VERSION ""

NS_ :

BS_:

BU_: XXX CAMERA FRONT_RADAR ADRV APRK

BO_ 53 ACCELERATOR: 32 XXX
 SG_ CHECKSUM : 0|16@1+ (1,0) [0|65535] "" XXX
 SG_ COUNTER : 16|8@1+ (1,0) [0|255] "" XXX
 SG_ ACCELERATOR_PEDAL : 40|8@1+ (1,0) [0|255] "" XXX
 SG_ GEAR : 192|3@1+ (1,0) [0|7] "" XXX

BO_ 64 GEAR_ALT: 32 XXX
 SG_ CHECKSUM : 0|16@1+ (1,0) [0|65535] "" XXX
 SG_ COUNTER : 16|8@1+ (1,0) [0|255] "" XXX
 SG_ GEAR : 32|3@1+ (1,0) [0|7] "" XXX

BO_ 69 GEAR: 24 XXX
 SG_ CHECKSUM : 0|16@1+ (1,0) [0|65535] "" XXX
 SG_ COUNTER : 16|8@1+ (1,0) [0|255] "" XXX
 SG_ GEAR : 44|3@1+ (1,0) [0|7] "" XXX

BO_ 96 ESP_STATUS: 32 XXX
 SG_ CHECKSUM : 0|16@1+ (1,0) [0|65535] "" XXX
 SG_ COUNTER : 16|8@1+ (1,0) [0|255] "" XXX
 SG_ TRACTION_AND_STABILITY_CONTROL : 42|3@1+ (1,0) [0|63] "" XXX
 SG_ BRAKE_PRESSURE : 128|10@1+ (1,0) [0|65535] "" XXX
 SG_ BRAKE_PRESSED : 148|1@1+ (1,0) [0|3] "" XXX

BO_ 101 BRAKE: 32 XXX
 SG_ CHECKSUM : 0|16@1+ (1,0) [0|65535] "" XXX
 SG_ COUNTER : 16|8@1+ (1,0) [0|255] "" XXX
 SG_ BRAKE_POSITION : 40|16@1- (1,0) [0|65535] "" XXX
 SG_ BRAKE_PRESSED : 57|1@1+ (1,0) [0|3] "" XXX

BO_ 160 WHEEL_SPEEDS: 24 XXX
 SG_ CHECKSUM : 0|16@1+ (1,0) [0|65535] "" XXX
 SG_ COUNTER : 16|8@1+ (1,0) [0|255] "" XXX
 SG_ MOVING_FORWARD : 56|1@0+ (1,0) [0|1] "" XXX
 SG_ MOVING_BACKWARD : 57|1@0+ (1,0) [0|1] "" XXX
 SG_ MOVING_FORWARD2 : 58|1@0+ (1,0) [0|1] "" XXX
 SG_ MOVING_BACKWARD2 : 59|1@0+ (1,0) [0|1] "" XXX
 SG_ WHL_SpdFLVal : 64|14@1+ (0.03125,0) [0|0] "km^h" XXX
 SG_ WHL_SpdFRVal : 80|14@1+ (0.03125,0) [0|0] "km^h" XXX
 SG_ WHL_SpdRLVal : 96|14@1+ (0.03125,0) [0|0] "km^h" XXX
 SG_ WHL_SpdRRVal : 112|14@1+ (0.03125,0) [0|0] "km^h" XXX

BO_ 256 ACCELERATOR_BRAKE_ALT: 32 XXX
 SG_ CHECKSUM : 0|16@1+ (1,0) [0|65535] "" XXX
 SG_ COUNTER : 16|8@1+ (1,0) [0|255] "" XXX
 SG_ BRAKE_PRESSED : 32|1@1+ (1,0) [0|1] "" XXX
 SG_ ACCELERATOR_PEDAL_PRESSED : 176|1@1+ (1,0) [0|1] "" XXX

BO_ 272 LKAS_ALT: 32 XXX
 SG_ CHECKSUM : 0|16@1+ (1,0) [0|65535] "" XXX
 SG_ COUNTER : 16|8@1+ (1,0) [0|255] "" XXX
 SG_ LKA_MODE : 24|3@1+ (1,0) [0|7] "" XXX
 SG_ LKA_AVAILABLE : 27|2@1+ (1,0) [0|255] "" XXX
 SG_ LKA_WARNING : 32|1@1+ (1,0) [0|1] "" XXX
 SG_ LKA_ICON : 38|2@1+ (1,0) [0|255] "" XXX
 SG_ FCA_SYSWARN : 40|1@0+ (1,0) [0|1] "" XXX
 SG_ TORQUE_REQUEST : 41|11@1+ (1,-1024) [0|4095] "" XXX
 SG_ STEER_REQ : 52|1@1+ (1,0) [0|1] "" XXX
 SG_ LFA_BUTTON : 56|1@1+ (1,0) [0|255] "" XXX
 SG_ LKA_ASSIST : 62|1@1+ (1,0) [0|1] "" XXX
 SG_ STEER_MODE : 65|3@1+ (1,0) [0|1] "" XXX
 SG_ NEW_SIGNAL_2 : 70|2@0+ (1,0) [0|3] "" XXX
 SG_ LKAS_ANGLE_ACTIVE : 77|2@0+ (1,0) [0|3] "" XXX
 SG_ HAS_LANE_SAFETY : 80|1@0+ (1,0) [0|1] "" XXX
 SG_ ADAS_StrAnglReqVal : 82|14@1- (0.1,0) [0|176.7] "Deg" GW_RGW,MDPS,SFA
 SG_ ADAS_ACIAnglTqRedcGainVal : 96|8@1+ (0.004,0) [0|1] "" GW_RGW,MDPS,SFA
 SG_ DAMP_FACTOR : 64|8@1+ (1,0) [0|255] "" XXX

BO_ 357 SPAS1: 24 APRK
 SG_ CHECKSUM : 0|16@1+ (1,0) [0|65535] "" XXX
 SG_ COUNTER : 16|8@1+ (1,0) [0|0] "" XXX
 SG_ NEW_SIGNAL_2 : 90|3@1+ (1,0) [0|0] "" XXX
 SG_ NEW_SIGNAL_1 : 96|16@1- (0.1,0) [0|0] "" XXX

BO_ 576 RADAR_0x240: 16 FRONT_RADAR
 SG_ CHECKSUM : 0|16@1+ (1,0) [0|65535] "" XXX
 SG_ COUNTER : 16|8@1+ (1,0) [0|255] "" XXX

BO_ 866 CAM_0x362: 32 CAMERA
 SG_ CHECKSUM : 0|16@1+ (1,0) [0|65535] "" XXX
 SG_ COUNTER : 16|8@1+ (1,0) [0|255] "" XXX
 SG_ BYTE3 : 24|8@1+ (1,0) [0|255] "" XXX
 SG_ BYTE4 : 32|8@1+ (1,0) [0|255] "" XXX
 SG_ BYTE5 : 40|8@1+ (1,0) [0|255] "" XXX
 SG_ BYTE6 : 48|8@1+ (1,0) [0|255] "" XXX
 SG_ LEFT_LANE_LINE : 56|2@1+ (1,0) [0|3] "" XXX
 SG_ SET_ME_0 : 58|2@1+ (1,0) [0|3] "" XXX
 SG_ RIGHT_LANE_LINE : 60|2@1+ (1,0) [0|3] "" XXX
 SG_ SET_ME_0_2 : 62|2@1+ (1,0) [0|3] "" XXX
 SG_ BYTE8 : 64|8@1+ (1,0) [0|255] "" XXX
 SG_ BYTE9 : 72|8@1+ (1,0) [0|255] "" XXX
 SG_ BYTE10 : 80|8@1+ (1,0) [0|255] "" XXX
 SG_ BYTE11 : 88|8@1+ (1,0) [0|255] "" XXX
 SG_ BYTE12 : 96|8@1+ (1,0) [0|255] "" XXX
 SG_ BYTE13 : 104|8@1+ (1,0) [0|255] "" XXX
 SG_ BYTE14 : 112|8@1+ (1,0) [0|255] "" XXX
 SG_ BYTE15 : 120|8@1+ (1,0) [0|255] "" XXX
 SG_ BYTE16 : 128|8@1+ (1,0) [0|255] "" XXX
 SG_ BYTE17 : 136|8@1+ (1,0) [0|255] "" XXX
 SG_ BYTE18 : 144|8@1+ (1,0) [0|255] "" XXX
 SG_ BYTE19 : 152|8@1+ (1,0) [0|255] "" XXX
 SG_ BYTE20 : 160|8@1+ (1,0) [0|255] "" XXX
 SG_ BYTE21 : 168|8@1+ (1,0) [0|255] "" XXX
 SG_ BYTE22 : 176|8@1+ (1,0) [0|255] "" XXX
 SG_ BYTE23 : 184|8@1+ (1,0) [0|255] "" XXX
 SG_ BYTE24 : 192|8@1+ (1,0) [0|255] "" XXX
 SG_ BYTE25 : 200|8@1+ (1,0) [0|255] "" XXX
 SG_ BYTE26 : 208|8@1+ (1,0) [0|255] "" XXX
 SG_ BYTE27 : 216|8@1+ (1,0) [0|255] "" XXX
 SG_ BYTE28 : 224|8@1+ (1,0) [0|255] "" XXX
 SG_ BYTE29 : 232|8@1+ (1,0) [0|255] "" XXX
 SG_ BYTE30 : 240|8@1+ (1,0) [0|255] "" XXX
 SG_ BYTE31 : 248|8@1+ (1,0) [0|255] "" XXX

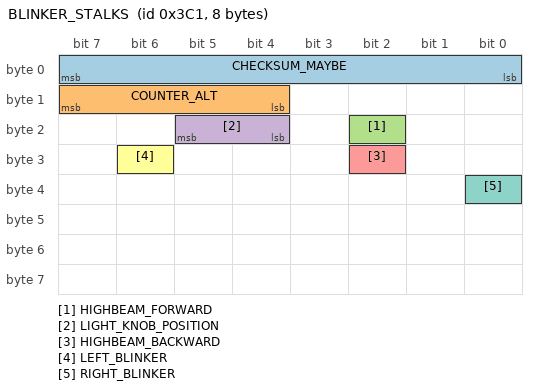
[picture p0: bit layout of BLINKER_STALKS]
BO_ 961 BLINKER_STALKS: 8 XXX
 SG_ CHECKSUM_MAYBE : 7|8@0+ (1,0) [0|255] "" XXX
 SG_ COUNTER_ALT : 15|4@0+ (1,0) [0|15] "" XXX
 SG_ HIGHBEAM_FORWARD : 18|1@0+ (1,0) [0|1] "" XXX
 SG_ LIGHT_KNOB_POSITION : 21|2@0+ (1,0) [0|3] "" XXX
 SG_ HIGHBEAM_BACKWARD : 26|1@0+ (1,0) [0|1] "" XXX
 SG_ LEFT_BLINKER : 30|1@0+ (1,0) [0|1] "" XXX
 SG_ RIGHT_BLINKER : 32|1@0+ (1,0) [0|1] "" XXX

BO_ 32 message_32: 8 Vector__XXX
 SG_ Signal_32 : 0|8@1+ (1,0) [0|0] "" Vector__XXX

BO_ 33 message_33: 8 Vector__XXX
 SG_ Signal_33 : 0|8@1+ (1,0) [0|0] "" Vector__XXX

BO_ 34 message_34: 8 Vector__XXX
 SG_ Signal_34 : 0|8@1+ (1,0) [0|0] "" Vector__XXX

BO_ 37 message_37: 8 Vector__XXX
 SG_ Signal_37 : 0|8@1+ (1,0) [0|0] "" Vector__XXX

BO_ 38 message_38: 8 Vector__XXX
 SG_ Signal_38 : 0|8@1+ (1,0) [0|0] "" Vector__XXX

BO_ 39 message_39: 8 Vector__XXX
 SG_ Signal_39 : 0|8@1+ (1,0) [0|0] "" Vector__XXX

BO_ 41 message_41: 8 Vector__XXX
 SG_ Signal_41 : 0|8@1+ (1,0) [0|0] "" Vector__XXX

BO_ 42 message_42: 8 Vector__XXX
 SG_ Signal_42 : 0|8@1+ (1,0) [0|0] "" Vector__XXX

BO_ 47 message_47: 8 Vector__XXX
 SG_ Signal_47 : 0|8@1+ (1,0) [0|0] "" Vector__XXX

BO_ 48 message_48: 8 Vector__XXX
 SG_ Signal_48 : 0|8@1+ (1,0) [0|0] "" Vector__XXX

BO_ 52 message_52: 8 Vector__XXX
 SG_ Signal_52 : 0|8@1+ (1,0) [0|0] "" Vector__XXX

BO_ 60 message_60: 8 Vector__XXX
 SG_ Signal_60 : 0|8@1+ (1,0) [0|0] "" Vector__XXX

BO_ 62 message_62: 8 Vector__XXX
 SG_ Signal_62 : 0|8@1+ (1,0) [0|0] "" Vector__XXX

BO_ 66 message_66: 8 Vector__XXX
 SG_ Signal_66 : 0|8@1+ (1,0) [0|0] "" Vector__XXX

BO_ 68 message_68: 8 Vector__XXX
 SG_ Signal_68 : 0|8@1+ (1,0) [0|0] "" Vector__XXX

BO_ 71 message_71: 8 Vector__XXX
 SG_ Signal_71 : 0|8@1+ (1,0) [0|0] "" Vector__XXX

BO_ 72 message_72: 8 Vector__XXX
 SG_ Signal_72 : 0|8@1+ (1,0) [0|0] "" Vector__XXX

BO_ 73 message_73: 8 Vector__XXX
 SG_ Signal_73 : 0|8@1+ (1,0) [0|0] "" Vector__XXX

BO_ 74 message_74: 8 Vector__XXX
 SG_ Signal_74 : 0|8@1+ (1,0) [0|0] "" Vector__XXX

BO_ 75 message_75: 8 Vector__XXX
 SG_ Signal_75 : 0|8@1+ (1,0) [0|0] "" Vector__XXX

BO_ 79 message_79: 8 Vector__XXX
 SG_ Signal_79 : 0|8@1+ (1,0) [0|0] "" Vector__XXX

BO_ 82 message_82: 8 Vector__XXX
 SG_ Signal_82 : 0|8@1+ (1,0) [0|0] "" Vector__XXX

BO_ 88 message_88: 8 Vector__XXX
 SG_ Signal_88 : 0|8@1+ (1,0) [0|0] "" Vector__XXX

BO_ 90 message_90: 8 Vector__XXX
 SG_ Signal_90 : 0|8@1+ (1,0) [0|0] "" Vector__XXX

BO_ 97 message_97: 8 Vector__XXX
 SG_ Signal_97 : 0|8@1+ (1,0) [0|0] "" Vector__XXX

BO_ 100 message_100: 8 Vector__XXX
 SG_ Signal_100 : 0|8@1+ (1,0) [0|0] "" Vector__XXX

BO_ 116 message_116: 8 Vector__XXX
 SG_ Signal_116 : 0|8@1+ (1,0) [0|0] "" Vector__XXX

BO_ 117 message_117: 8 Vector__XXX
 SG_ Signal_117 : 0|8@1+ (1,0) [0|0] "" Vector__XXX

BO_ 118 message_118: 8 Vector__XXX
 SG_ Signal_118 : 0|8@1+ (1,0) [0|0] "" Vector__XXX

BO_ 119 message_119: 8 Vector__XXX
 SG_ Signal_119 : 0|8@1+ (1,0) [0|0] "" Vector__XXX

BO_ 125 message_125: 8 Vector__XXX
 SG_ Signal_125 : 0|8@1+ (1,0) [0|0] "" Vector__XXX

BO_ 126 message_126: 8 Vector__XXX
 SG_ Signal_126 : 0|8@1+ (1,0) [0|0] "" Vector__XXX

BO_ 127 message_127: 8 Vector__XXX
 SG_ Signal_127 : 0|8@1+ (1,0) [0|0] "" Vector__XXX

BO_ 128 message_128: 8 Vector__XXX
 SG_ Signal_128 : 0|8@1+ (1,0) [0|0] "" Vector__XXX

BO_ 129 message_129: 8 Vector__XXX
 SG_ Signal_129 : 0|8@1+ (1,0) [0|0] "" Vector__XXX

BO_ 130 message_130: 8 Vector__XXX
 SG_ Signal_130 : 0|8@1+ (1,0) [0|0] "" Vector__XXX

BO_ 140 message_140: 8 Vector__XXX
 SG_ Signal_140 : 0|8@1+ (1,0) [0|0] "" Vector__XXX

BO_ 145 message_145: 8 Vector__XXX
 SG_ Signal_145 : 0|8@1+ (1,0) [0|0] "" Vector__XXX

BO_ 148 message_148: 8 Vector__XXX
 SG_ Signal_148 : 0|8@1+ (1,0) [0|0] "" Vector__XXX

BO_ 171 message_171: 8 Vector__XXX
 SG_ Signal_171 : 0|8@1+ (1,0) [0|0] "" Vector__XXX

BO_ 172 message_172: 8 Vector__XXX
 SG_ Signal_172 : 0|8@1+ (1,0) [0|0] "" Vector__XXX

BO_ 173 message_173: 8 Vector__XXX
 SG_ Signal_173 : 0|8@1+ (1,0) [0|0] "" Vector__XXX

BO_ 175 message_175: 8 Vector__XXX
 SG_ Signal_175 : 0|8@1+ (1,0) [0|0] "" Vector__XXX

BO_ 177 message_177: 8 Vector__XXX
 SG_ Signal_177 : 0|8@1+ (1,0) [0|0] "" Vector__XXX

BO_ 178 message_178: 8 Vector__XXX
 SG_ Signal_178 : 0|8@1+ (1,0) [0|0] "" Vector__XXX

BO_ 182 message_182: 8 Vector__XXX
 SG_ Signal_182 : 0|8@1+ (1,0) [0|0] "" Vector__XXX

BO_ 184 message_184: 8 Vector__XXX
 SG_ Signal_184 : 0|8@1+ (1,0) [0|0] "" Vector__XXX

BO_ 185 message_185: 8 Vector__XXX
 SG_ Signal_185 : 0|8@1+ (1,0) [0|0] "" Vector__XXX

BO_ 186 message_186: 8 Vector__XXX
 SG_ Signal_186 : 0|8@1+ (1,0) [0|0] "" Vector__XXX

BO_ 194 message_194: 8 Vector__XXX
 SG_ Signal_194 : 0|8@1+ (1,0) [0|0] "" Vector__XXX

BO_ 204 message_204: 8 Vector__XXX
 SG_ Signal_204 : 0|8@1+ (1,0) [0|0] "" Vector__XXX

BO_ 209 message_209: 8 Vector__XXX
 SG_ Signal_209 : 0|8@1+ (1,0) [0|0] "" Vector__XXX

BO_ 221 message_221: 8 Vector__XXX
 SG_ Signal_221 : 0|8@1+ (1,0) [0|0] "" Vector__XXX

BO_ 240 message_240: 8 Vector__XXX
 SG_ Signal_240 : 0|8@1+ (1,0) [0|0] "" Vector__XXX

BO_ 247 message_247: 8 Vector__XXX
 SG_ Signal_247 : 0|8@1+ (1,0) [0|0] "" Vector__XXX

BO_ 258 message_258: 8 Vector__XXX
 SG_ Signal_258 : 0|8@1+ (1,0) [0|0] "" Vector__XXX

BO_ 268 message_268: 8 Vector__XXX
 SG_ Signal_268 : 0|8@1+ (1,0) [0|0] "" Vector__XXX

BO_ 285 message_285: 8 Vector__XXX
 SG_ Signal_285 : 0|8@1+ (1,0) [0|0] "" Vector__XXX

BO_ 303 message_303: 8 Vector__XXX
 SG_ Signal_303 : 0|8@1+ (1,0) [0|0] "" Vector__XXX

BO_ 321 message_321: 8 Vector__XXX
 SG_ Signal_321 : 0|8@1+ (1,0) [0|0] "" Vector__XXX

BO_ 327 message_327: 8 Vector__XXX
 SG_ Signal_327 : 0|8@1+ (1,0) [0|0] "" Vector__XXX

BO_ 328 message_328: 8 Vector__XXX
 SG_ Signal_328 : 0|8@1+ (1,0) [0|0] "" Vector__XXX

BO_ 560 message_560: 8 Vector__XXX
 SG_ Signal_560 : 0|8@1+ (1,0) [0|0] "" Vector__XXX

BO_ 565 message_565: 8 Vector__XXX
 SG_ Signal_565 : 0|8@1+ (1,0) [0|0] "" Vector__XXX

BO_ 566 message_566: 8 Vector__XXX
 SG_ Signal_566 : 0|8@1+ (1,0) [0|0] "" Vector__XXX

BO_ 567 message_567: 8 Vector__XXX
 SG_ Signal_567 : 0|8@1+ (1,0) [0|0] "" Vector__XXX

BO_ 568 message_568: 8 Vector__XXX
 SG_ Signal_568 : 0|8@1+ (1,0) [0|0] "" Vector__XXX

BO_ 569 message_569: 8 Vector__XXX
 SG_ Signal_569 : 0|8@1+ (1,0) [0|0] "" Vector__XXX

BO_ 570 message_570: 8 Vector__XXX
 SG_ Signal_570 : 0|8@1+ (1,0) [0|0] "" Vector__XXX

BO_ 571 message_571: 8 Vector__XXX
 SG_ Signal_571 : 0|8@1+ (1,0) [0|0] "" Vector__XXX

BO_ 572 message_572: 8 Vector__XXX
 SG_ Signal_572 : 0|8@1+ (1,0) [0|0] "" Vector__XXX

BO_ 573 message_573: 8 Vector__XXX
 SG_ Signal_573 : 0|8@1+ (1,0) [0|0] "" Vector__XXX

BO_ 574 message_574: 8 Vector__XXX
 SG_ Signal_574 : 0|8@1+ (1,0) [0|0] "" Vector__XXX

BO_ 575 message_575: 8 Vector__XXX
 SG_ Signal_575 : 0|8@1+ (1,0) [0|0] "" Vector__XXX

BO_ 577 message_577: 8 Vector__XXX
 SG_ Signal_577 : 0|8@1+ (1,0) [0|0] "" Vector__XXX

BO_ 578 message_578: 8 Vector__XXX
 SG_ Signal_578 : 0|8@1+ (1,0) [0|0] "" Vector__XXX

BO_ 579 message_579: 8 Vector__XXX
 SG_ Signal_579 : 0|8@1+ (1,0) [0|0] "" Vector__XXX

BO_ 580 message_580: 8 Vector__XXX
 SG_ Signal_580 : 0|8@1+ (1,0) [0|0] "" Vector__XXX

BO_ 581 message_581: 8 Vector__XXX
 SG_ Signal_581 : 0|8@1+ (1,0) [0|0] "" Vector__XXX

BO_ 582 message_582: 8 Vector__XXX
 SG_ Signal_582 : 0|8@1+ (1,0) [0|0] "" Vector__XXX

BO_ 583 message_583: 8 Vector__XXX
 SG_ Signal_583 : 0|8@1+ (1,0) [0|0] "" Vector__XXX

BO_ 584 message_584: 8 Vector__XXX
 SG_ Signal_584 : 0|8@1+ (1,0) [0|0] "" Vector__XXX

BO_ 752 message_752: 8 Vector__XXX
 SG_ Signal_752 : 0|8@1+ (1,0) [0|0] "" Vector__XXX

BO_ 768 message_768: 8 Vector__XXX
 SG_ Signal_768 : 0|8@1+ (1,0) [0|0] "" Vector__XXX

BO_ 771 message_771: 8 Vector__XXX
 SG_ Signal_771 : 0|8@1+ (1,0) [0|0] "" Vector__XXX

BO_ 864 message_864: 8 Vector__XXX
 SG_ Signal_864 : 0|8@1+ (1,0) [0|0] "" Vector__XXX

BO_ 865 message_865: 8 Vector__XXX
 SG_ Signal_865 : 0|8@1+ (1,0) [0|0] "" Vector__XXX

BO_ 867 message_867: 8 Vector__XXX
 SG_ Signal_867 : 0|8@1+ (1,0) [0|0] "" Vector__XXX

BO_ 868 message_868: 8 Vector__XXX
 SG_ Signal_868 : 0|8@1+ (1,0) [0|0] "" Vector__XXX

BO_ 896 message_896: 8 Vector__XXX
 SG_ Signal_896 : 0|8@1+ (1,0) [0|0] "" Vector__XXX

BO_ 917 message_917: 8 Vector__XXX
 SG_ Signal_917 : 0|8@1+ (1,0) [0|0] "" Vector__XXX

BO_ 928 message_928: 8 Vector__XXX
 SG_ Signal_928 : 0|8@1+ (1,0) [0|0] "" Vector__XXX

BO_ 933 message_933: 8 Vector__XXX
 SG_ Signal_933 : 0|8@1+ (1,0) [0|0] "" Vector__XXX

BO_ 934 message_934: 8 Vector__XXX
 SG_ Signal_934 : 0|8@1+ (1,0) [0|0] "" Vector__XXX

BO_ 935 message_935: 8 Vector__XXX
 SG_ Signal_935 : 0|8@1+ (1,0) [0|0] "" Vector__XXX

BO_ 936 message_936: 8 Vector__XXX
 SG_ Signal_936 : 0|8@1+ (1,0) [0|0] "" Vector__XXX

BO_ 937 message_937: 8 Vector__XXX
 SG_ Signal_937 : 0|8@1+ (1,0) [0|0] "" Vector__XXX

BO_ 938 message_938: 8 Vector__XXX
 SG_ Signal_938 : 0|8@1+ (1,0) [0|0] "" Vector__XXX

BO_ 939 message_939: 8 Vector__XXX
 SG_ Signal_939 : 0|8@1+ (1,0) [0|0] "" Vector__XXX

BO_ 940 message_940: 8 Vector__XXX
 SG_ Signal_940 : 0|8@1+ (1,0) [0|0] "" Vector__XXX

BO_ 941 message_941: 8 Vector__XXX
 SG_ Signal_941 : 0|8@1+ (1,0) [0|0] "" Vector__XXX

BO_ 942 message_942: 8 Vector__XXX
 SG_ Signal_942 : 0|8@1+ (1,0) [0|0] "" Vector__XXX

BO_ 943 message_943: 8 Vector__XXX
 SG_ Signal_943 : 0|8@1+ (1,0) [0|0] "" Vector__XXX

BO_ 944 message_944: 8 Vector__XXX
 SG_ Signal_944 : 0|8@1+ (1,0) [0|0] "" Vector__XXX

BO_ 945 message_945: 8 Vector__XXX
 SG_ Signal_945 : 0|8@1+ (1,0) [0|0] "" Vector__XXX

BO_ 946 message_946: 8 Vector__XXX
 SG_ Signal_946 : 0|8@1+ (1,0) [0|0] "" Vector__XXX

BO_ 947 message_947: 8 Vector__XXX
 SG_ Signal_947 : 0|8@1+ (1,0) [0|0] "" Vector__XXX

BO_ 948 message_948: 8 Vector__XXX
 SG_ Signal_948 : 0|8@1+ (1,0) [0|0] "" Vector__XXX

BO_ 949 message_949: 8 Vector__XXX
 SG_ Signal_949 : 0|8@1+ (1,0) [0|0] "" Vector__XXX

BO_ 950 message_950: 8 Vector__XXX
 SG_ Signal_950 : 0|8@1+ (1,0) [0|0] "" Vector__XXX

BO_ 951 message_951: 8 Vector__XXX
 SG_ Signal_951 : 0|8@1+ (1,0) [0|0] "" Vector__XXX

BO_ 952 message_952: 8 Vector__XXX
 SG_ Signal_952 : 0|8@1+ (1,0) [0|0] "" Vector__XXX

BO_ 953 message_953: 8 Vector__XXX
 SG_ Signal_953 : 0|8@1+ (1,0) [0|0] "" Vector__XXX

BO_ 954 message_954: 8 Vector__XXX
 SG_ Signal_954 : 0|8@1+ (1,0) [0|0] "" Vector__XXX

BO_ 955 message_955: 8 Vector__XXX
 SG_ Signal_955 : 0|8@1+ (1,0) [0|0] "" Vector__XXX

BO_ 956 message_956: 8 Vector__XXX
 SG_ Signal_956 : 0|8@1+ (1,0) [0|0] "" Vector__XXX

BO_ 957 message_957: 8 Vector__XXX
 SG_ Signal_957 : 0|8@1+ (1,0) [0|0] "" Vector__XXX

BO_ 958 message_958: 8 Vector__XXX
 SG_ Signal_958 : 0|8@1+ (1,0) [0|0] "" Vector__XXX

BO_ 959 message_959: 8 Vector__XXX
 SG_ Signal_959 : 0|8@1+ (1,0) [0|0] "" Vector__XXX

BO_ 960 message_960: 8 Vector__XXX
 SG_ Signal_960 : 0|8@1+ (1,0) [0|0] "" Vector__XXX

BO_ 962 message_962: 8 Vector__XXX
 SG_ Signal_962 : 0|8@1+ (1,0) [0|0] "" Vector__XXX

BO_ 963 message_963: 8 Vector__XXX
 SG_ Signal_963 : 0|8@1+ (1,0) [0|0] "" Vector__XXX

BO_ 964 message_964: 8 Vector__XXX
 SG_ Signal_964 : 0|8@1+ (1,0) [0|0] "" Vector__XXX

BO_ 975 message_975: 8 Vector__XXX
 SG_ Signal_975 : 0|8@1+ (1,0) [0|0] "" Vector__XXX

BO_ 976 message_976: 8 Vector__XXX
 SG_ Signal_976 : 0|8@1+ (1,0) [0|0] "" Vector__XXX

BO_ 977 message_977: 8 Vector__XXX
 SG_ Signal_977 : 0|8@1+ (1,0) [0|0] "" Vector__XXX

BO_ 978 message_978: 8 Vector__XXX
 SG_ Signal_978 : 0|8@1+ (1,0) [0|0] "" Vector__XXX

BO_ 979 message_979: 8 Vector__XXX
 SG_ Signal_979 : 0|8@1+ (1,0) [0|0] "" Vector__XXX

BO_ 980 message_980: 8 Vector__XXX
 SG_ Signal_980 : 0|8@1+ (1,0) [0|0] "" Vector__XXX

BO_ 984 message_984: 8 Vector__XXX
 SG_ Signal_984 : 0|8@1+ (1,0) [0|0] "" Vector__XXX

BO_ 1024 message_1024: 8 Vector__XXX
 SG_ Signal_1024 : 0|8@1+ (1,0) [0|0] "" Vector__XXX

BO_ 1200 message_1200: 8 Vector__XXX
 SG_ Signal_1200 : 0|8@1+ (1,0) [0|0] "" Vector__XXX

BO_ 1280 message_1280: 8 Vector__XXX
 SG_ Signal_1280 : 0|8@1+ (1,0) [0|0] "" Vector__XXX

CM_ "AUTOGENERATED FILE, DO NOT EDIT";
CM_ "Imported file _hyundai_canfd_common.dbc starts here";
CM_ BO_ 676 "Contains signals with detailed lane line information. Used by ADAS ECU on HDA 2 vehicles to operate LFA.";

CM_ SG_ 80 HAS_LANE_SAFETY "If 0, hides LKAS 'Lane Safety' menu from vehicle settings";
CM_ SG_ 676 LEFT_LANE_LINE "Left lane line confidence";
CM_ SG_ 676 RIGHT_LANE_LINE "Right lane line confidence";
VAL_ 80 LKA_ICON 0 "hidden" 1 "grey" 2 "green" 3 "flashing green" ;
VAL_ 80 LKA_MODE 1 "warning only" 2 "assist" 6 "off" ;
VAL_ 676 LEFT_LANE_LINE 0 "Not Detected" 1 "Low Confidence" 2 "Medium Confidence" 3 "High Confidence";
VAL_ 676 RIGHT_LANE_LINE 0 "Not Detected" 1 "Low Confidence" 2 "Medium Confidence" 3 "High Confidence";

CM_ "hyundai_canfd.dbc starts here";

CM_ SG_ 96 BRAKE_PRESSURE "User applied brake pedal pressure. Ramps from computer applied pressure on falling edge of cruise. Cruise cancels if !=0";
CM_ SG_ 101 BRAKE_POSITION "User applied brake pedal position, max is ~700. Signed on some vehicles";
CM_ SG_ 203 ADAS_ActvACISta "ADAS Active AngleControlInterface State";
CM_ SG_ 203 ADAS_ActvACILvl2Sta "ADAS Active AngleControlInterface Level 2 State";
CM_ SG_ 203 ADAS_StrAnglReqVal "(LFA) ADAS Steering Angle Request Value; Capped at 119.9;";
CM_ SG_ 203 ADAS_ACIAnglTqRedcGainVal "(LFA) ADAS AngleControlInterface Angle Torque Reduction Gain Value";
CM_ SG_ 203 FCA_ESA_ActvSta "FCA_ESA Active State";
CM_ SG_ 203 FCA_ESA_TqBstGainVal "FCA_ESA Torque Boost Gain Value";
CM_ BO_ 272 "Alternative LKAS message, used on cars such as 2023 Ioniq 6, 2nd gen Kona. Matches LKAS except size is 32 bytes";
CM_ SG_ 272 LKA_AVAILABLE "Angle control cars: 3 when LKA is generally available, goes to 0 during changes with LFA";
CM_ SG_ 272 ADAS_StrAnglReqVal "(LKAS) ADAS Steering Angle Request Value; Capped at 176.7; tracks MDPS->STEERING_ANGLE when not engaged, not STEERING_SENSORS->STEERING_ANGLE";
CM_ SG_ 272 ADAS_ACIAnglTqRedcGainVal "(LKAS) ADAS AngleControlInterface Angle Torque Reduction Gain Value";
CM_ BO_ 282 "Sent by the camera containing DAW (Driver Attention Warning) information and information about HBA (High Beam Assist).";
CM_ SG_ 282 FR_CMR_Crc1Val "The data area for CRC calculation is based on the data length (DLC) of the message DB. The CRC shall be calculated over the entire data block (excluding the CRC bytes) including the user data, alive counter and Data ID - CRC Polynomial (0x1021) , In";
CM_ SG_ 282 FR_CMR_AlvCnt1Val "For the first transmission request for a data element the counter shall be initialized with 0 and shall be incremented by 1 for every subsequent send request. When the counter reaches the maximum value(0xFF), then it shall restart with 0 for the next s";
CM_ SG_ 282 HBA_SysOptSta "HBA System Option Information to Lamp Controller";
CM_ SG_ 282 HBA_SysSta "This signal indicates the status of High Beam Assist system.";
CM_ SG_ 282 HBA_IndLmpReq "HBA System Indicator Lamp Status";
CM_ SG_ 282 FCA_Equip_MFC "FCA Sensor Type";
CM_ SG_ 282 HBA_OptUsmSta "HBA Option USM Status";
CM_ SG_ 282 DAW_LVDA_PUDis "Message for displaying LVDA(Leading Vehicle Departure Alert) Warning";
CM_ SG_ 282 DAW_LVDA_OptUsmSta "LVDA USM state";
CM_ SG_ 282 DAW_OptUsmSta "This signal represents the lastest DAW ON/OFF value of USM.";
CM_ SG_ 282 DAW_SysSta "This signal represents Attention Assist System Status or Attention Level.";
CM_ SG_ 282 DAW_WrnMsgSta "0x1 value requests DAW Rest recommend warning message popup at CLU. 0x2 value requests HDA/LFA Hands-Off call at TMS.";
CM_ SG_ 282 DAW_TimeRstReq "This signal requests CLU 'Last Break Time' Reset. DAW send '0x1' when detecting driver's rest.";
CM_ SG_ 282 DAW_SnstvtyModRetVal "This signal represents the feedback value of the current ADAS warning timing.";
CM_ SG_ 282 FR_CMR_SCCEquipSta "This signal indicates equipment for SCC";
CM_ SG_ 282 FR_CMR_ReqADASMapMsgVal "This signal indicates an ADAS map message request from FR_CMR to H_U. Each bit indicates the request messages as follows. - Bit 0 : H_U_NAVI_V2_STUB_E - Bit 1 : HU_NAVI_V2_PROSHORT_E_00 (곡률) - Bit 2 : HU_NAVI_V2_PROSHORT_E_00 (곡률 외 정보)";
CM_ SG_ 282 FR_CMR_SwVer1Val "This signal indicates a major version of FR_CMR software. If FR_CMR software version is A.00, 'A' and '00' mean major and minor version respectively.";
CM_ SG_ 282 FR_CMR_SwVer2Val "This signal indicates a minor version of FR_CMR software. If FR_CMR software version is A.00, 'A' and '00' mean major and minor version respectively.";
CM_ SG_ 298 NEW_SIGNAL_4 "todo: figure out why always set to 9";
CM_ SG_ 352 SET_ME_9 "has something to do with AEB settings";
CM_ SG_ 373 ACCEnable "Likely a copy of CAN's TCS13->ACCEnable";
CM_ SG_ 373 DriverBraking "Likely derived from BRAKE->BRAKE_POSITION";
CM_ SG_ 373 DriverBrakingLowSens "Higher threshold version of DriverBraking";
CM_ SG_ 373 PROBABLY_EQUIP "aeb equip?";
CM_ SG_ 416 VSetDis "set speed in display units";
CM_ BO_ 437 "Sent by the camera containing lane and lead information.";
CM_ SG_ 437 FR_CMR_Crc3Val "The data area for CRC calculation is based on the data length (DLC) of the message DB. The CRC shall be calculated over the entire data block (excluding the CRC bytes) including the user data, alive counter and Data ID - CRC Polynomial (0x1021) , In";
CM_ SG_ 437 FR_CMR_AlvCnt3Val "For the first transmission request for a data element the counter shall be initialized with 0 and shall be incremented by 1 for every subsequent send request. When the counter reaches the maximum value(0xFF), then it shall restart with 0 for the next s";
CM_ SG_ 437 Info_LftLnQualSta "This signal indicates the quality of left line.";
CM_ SG_ 437 Info_LftLnDptSta "This signal indicates the lane departure status of left line.";
CM_ SG_ 437 Info_LftLnPosVal "This signal outputs the position of left line from camera center.";
CM_ SG_ 437 Info_LftLnHdingAnglVal "This signal outputs the heading angle of left line.";
CM_ SG_ 437 Info_LftLnCvtrVal "This signal outputs the curvature of left line.";
CM_ SG_ 437 Info_RtLnQualSta "This signal indicates the quality of right line.";
CM_ SG_ 437 Info_RtLnDptSta "This signal indicates the lane departure status of right line.";
CM_ SG_ 437 Info_RtLnPosVal "This signal outputs the position of right line from camera center.";
CM_ SG_ 437 Info_RtLnHdingAnglVal "This signal outputs the heading angle of right line.";
CM_ SG_ 437 Info_RtLnCvtrVal "This signal outputs the curvature of right line.";
CM_ SG_ 437 ID_CIPV "Valid Object = 1 to 255 - ID detected by front camera can vary depending on vehicle environment. - Additional logic would be required to apply this signal for ISG.";
CM_ SG_ 437 Relative_Velocity "+ : Preceding, - : Oncoming - Velocity detected by front camera can vary depending on vehicle environment. - Additional logic would be required to apply this signal for ISG. - Confirmaiton by Autonomous Driving Engineering Team is required to use ID_C";
CM_ SG_ 480 NEW_SIGNAL_5 "todo: figure out why always set to 1";
CM_ BO_ 506 "Sent by the camera containing speed limit information. ISLW stands for Intelligent Speed Limit Warning, and ISLA is Intelligent Speed Limit Assist. it also contains road sign information.";
CM_ SG_ 506 FR_CMR_Crc2Val "The data area for CRC calculation is based on the data length (DLC) of the message DB.The CRC shall be calculated over the entire data block (excluding the CRC bytes) including the user data, alive counter and Data ID - CRC Polynomial (0x1021) , In";
CM_ SG_ 506 FR_CMR_AlvCnt2Val "For the first transmission request for a data element the counter shall be initialized with 0 and shall be incremented by 1 for every subsequent send request. When the counter reaches the maximum value(0xFF), then it shall restart with 0 for the next s";
CM_ SG_ 506 ISLW_OptUsmSta "ISLW option information";
CM_ SG_ 506 ISLW_SysSta "Validity of ISLW information";
CM_ SG_ 506 ISLW_NoPassingInfoDis "This signal indicates additional information of ISLW. For example no passing.";
CM_ SG_ 506 ISLW_OvrlpSignDis "indicates presence of Overlap sign";
CM_ SG_ 506 ISLW_SpdCluMainDis "Main Speed Information for cluster display in main page(0x1~0xFCH: 1*(HEX VALUE) [KPH or MPH :Reference signal is  CF_Clu_SPEED_UNIT of CLU])";
CM_ SG_ 506 ISLW_SpdNaviMainDis "Main Speed information for navigation display in main page(0x1~0xFCH: 1*(HEX VALUE) [KPH or MPH :Reference signal is  Navi_ISLW_SpdUnit of Navigation)";
CM_ SG_ 506 ISLW_SubCondinfoSta1 "Indicates 1st conditional traffic sign status";
CM_ SG_ 506 ISLW_SubCondinfoSta2 "Indicates 2nd conditional traffic sign status";
CM_ SG_ 506 ISLW_SpdCluSubMainDis "Main Speed Information for cluster display in ISLW detail page";
CM_ SG_ 506 ISLW_SpdCluDisSubCond1 "Indicates conditional speed limit/no passing of 1st conditional traffic sign for Cluster in ISLW Detail page";
CM_ SG_ 506 ISLW_SpdCluDisSubCond2 "Indicates conditional speed limit/no passing of 2nd conditional traffic sign for Cluster in ISLW Detail page";
CM_ SG_ 506 ISLW_SpdNaviSubMainDis "Main Speed Information for NAVI display in ISLW detail page";
CM_ SG_ 506 ISLW_SpdNaviDisSubCond1 "Indicates conditional speed limit/no passing of 1st conditional traffic sign for NAVI in ISLW Detail page";
CM_ SG_ 506 ISLW_SpdNaviDisSubCond2 "Indicates conditional speed limit/no passing of 2nd conditional traffic sign for NAVI in ISLW Detail page";
CM_ SG_ 506 ISLA_SpdwOffst "This is a ISLA speed with offset to change the set speed of MSLA/CC/SCC.Unit (kph or mph) refers to cluster signal: CLU_SpdUnitTyp@CLU_01_20ms";
CM_ SG_ 506 ISLA_SwIgnoreReq "This is a signal requesting to ignore the -(SET) or +(SET) switch input of the driver.";
CM_ SG_ 506 ISLA_SpdChgReq "This is a signal requesting to change the set speed of MSLA/CC/SCC to the ISLA speed.";
CM_ SG_ 506 ISLA_SpdWrn "This is a warning signal when VANZ exceeds the speed limit.";
CM_ SG_ 506 ISLA_IcyWrn "This is a warning signal when the snow or ice sign is recognized when it is less than 4 'C.";
CM_ SG_ 506 ISLA_SymFlashMod "This is a signal for the flashing mode of the symbol.";
CM_ SG_ 506 ISLA_Popup "This is a signal for ISLA pop-up.";
CM_ SG_ 506 ISLA_OptUsmSta "This is a ISLA option USM signal set by the driver.";
CM_ SG_ 506 ISLA_OffstUsmSta "This is a signal for offset speed set by the driver. Unit (kph or mph) refers to cluster signal: CLU_SpdUnitTyp@CLU_01_20ms";
CM_ SG_ 506 ISLA_AutoUsmSta "This is a signal for ISLA AUTO USM set by the driver.";
CM_ SG_ 506 ISLA_Cntry "This is a signal for categorizing countries";
CM_ SG_ 506 ISLA_AddtnlSign "This is a signal for additional sign";
CM_ SG_ 506 ISLA_SchoolZone "This is a signal for School Zone";
CM_ SG_ 687 HOD_Dir_Status "This signal indicates the status of hands on/off";
CM_ BO_ 698 "Sent by the camera containing information about vehicles in front of us. IFS stands for Intelligent Front-lighting System, and this signal provides the information necessary for it to operate.";
CM_ SG_ 698 FR_CMR_Crc4Val "The data area for CRC calculation is based on the data length (DLC) of the message DB. The CRC shall be calculated over the entire data block (excluding the CRC bytes) including the user data, alive counter and Data ID - CRC Polynomial (0x1021) , In";
CM_ SG_ 698 FR_CMR_AlvCnt4Val "For the first transmission request for a data element the counter shall be initialized with 0 and shall be incremented by 1 for every subsequent send request. When the counter reaches the maximum value(0xFF), then it shall restart with 0 for the next s";
CM_ SG_ 698 IFSref_FR_CMR_Sta "This is IFS system status needed for operate the IFS function of headlamp highbeam";
CM_ SG_ 698 IFSref_VehNumVal "This is number of vehicles detected from camera";
CM_ SG_ 698 IFSref_ILLAmbtSta "This signal is status of the ambient brightness 0x0 is bright condition (HighBeam off), 0x1 is dark condition (None)";
CM_ SG_ 698 IFSref_VehLftAngl1Val "This is left angle of vehicle 1 Deg = (HEX)*0.1-25";
CM_ SG_ 698 IFSref_VehRtAngl1Val "This is right angle of vehicle 1 Deg = (HEX)*0.1-25";
CM_ SG_ 698 IFSref_VehLftAngl2Val "This is left angle of vehicle 2 Deg = (HEX)*0.1-25";
CM_ SG_ 698 IFSref_VehDst1Val "IFSref_VehicleDistance1Value";
CM_ SG_ 698 IFSref_VehRtAngl2Val "This is right angle of vehicle 2 Deg = (HEX)*0.1-25";
CM_ SG_ 698 IFSref_VehLftAngl3Val "This is left angle of vehicle 3 Deg = (HEX)*0.1-25";
CM_ SG_ 698 IFSref_VehRtAngl3Val "This is right angle of vehicle 3 Deg = (HEX)*0.1-25";
CM_ SG_ 698 IFSref_VehLftAngl4Val "This is left angle of vehicle 4 Deg = (HEX)*0.1-25";
CM_ SG_ 698 IFSref_VehRtAngl4Val "This is right angle of vehicle 4 Deg = (HEX)*0.1-25";
CM_ SG_ 698 IFSref_VehLftAngl5Val "This is left angle of vehicle 5 Deg = (HEX)*0.1-25";
CM_ SG_ 698 IFSref_VehRtAngl5Val "This is right angle of vehicle 5 Deg = (HEX)*0.1-25";
CM_ SG_ 698 IFSref_VehLftAngl6Val "This is left angle of vehicle 6 Deg = (HEX)*0.1-25";
CM_ SG_ 698 IFSref_VehRtAngl6Val "This is right angle of vehicle 6 Deg = (HEX)*0.1-25";
CM_ SG_ 698 IFSref_VehLftAngl7Val "This is left angle of vehicle 7 Deg = (HEX)*0.1-25";
CM_ SG_ 698 IFSref_VehRtAngl7Val "This is right angle of vehicle 7 Deg = (HEX)*0.1-25";
CM_ SG_ 698 IFSref_VehLftAngl8Val "This is left angle of vehicle 8 Deg = (HEX)*0.1-25";
CM_ SG_ 698 IFSref_VehRtAngl8Val "This is right angle of vehicle 8 Deg = (HEX)*0.1-25";
CM_ SG_ 698 IFSref_VehLftAngl9Val "This is left angle of vehicle 9 Deg = (HEX)*0.1-25";
CM_ SG_ 698 IFSref_VehRtAngl9Val "This is right angle of vehicle 9 Deg = (HEX)*0.1-25";
CM_ SG_ 698 IFSref_VehLftAngl10Val "This is left angle of vehicle 10 Deg = (HEX)*0.1-25";
CM_ SG_ 698 IFSref_VehRtAngl10Val "This is right angle of vehicle 10 Deg = (HEX)*0.1-25";
CM_ SG_ 698 IFSref_VehDst2Val "IFSref_VehicleDistance2Value";
CM_ SG_ 698 IFSref_VehDst3Val "IFSref_VehicleDistance3Value";
CM_ SG_ 698 IFSref_VehDst4Val "IFSref_VehicleDistance4Value";
CM_ SG_ 698 IFSref_VehDst5Val "IFSref_VehicleDistance5Value";
CM_ SG_ 698 IFSref_VehDst6Val "IFSref_VehicleDistance6Value";
CM_ SG_ 698 IFSref_VehDst7Val "IFSref_VehicleDistance7Value";
CM_ SG_ 698 IFSref_VehDst8Val "IFSref_VehicleDistance8Value";
CM_ SG_ 698 IFSref_VehDst9Val "IFSref_VehicleDistance9Value";
CM_ SG_ 698 IFSref_VehDst10Val "IFSref_VehicleDistance10Value";
CM_ SG_ 736 MAX_SPEED "Display units. Restricts car from driving above this speed unless accelerator pedal is depressed beyond pressure point";
CM_ BO_ 866 "Contains signals with detailed lane line information. Used by ADAS ECU on HDA 2 vehicles to operate LFA. Used on cars that use message 272.";
CM_ SG_ 866 LEFT_LANE_LINE "Left lane line confidence";
CM_ SG_ 866 RIGHT_LANE_LINE "Right lane line confidence";
CM_ SG_ 961 COUNTER_ALT "only increments on change";
CM_ SG_ 1041 COUNTER_ALT "only increments on change";
CM_ BO_ 1043 "Lamp signals do not seem universal on cars that use LKAS_ALT, but stalk signals do.";
CM_ SG_ 1043 COUNTER_ALT "only increments on change";
CM_ SG_ 1043 USE_ALT_LAMP "likely 1 on cars that use alt lamp signals";
VAL_ 53 GEAR 0 "P" 5 "D" 6 "N" 7 "R";
VAL_ 64 GEAR 0 "P" 5 "D" 6 "N" 7 "R";
VAL_ 69 GEAR 0 "P" 5 "D" 6 "N" 7 "R";
VAL_ 96 TRACTION_AND_STABILITY_CONTROL 0 "On" 5 "Limited" 1 "Off";
VAL_ 112 GEAR 0 "P" 5 "D" 6 "N" 7 "R";
VAL_ 203 ADAS_ActvACISta 0 "INIT" 1 "INACTIVE" 2 "ACTIVE35(ACTIVE)" 3 "ACTIVE33(Redundancy)" 4 "RESERVED" 5 "RESERVED" 6 "RESERVED" 7 "RESERVED" 8 "RESERVED" 9 "RESERVED" 10 "RESERVED" 11 "RESERVED" 12 "RESERVED" 13 "RESERVED" 14 "RESERVED" 15 "RESERVED";
VAL_ 203 ADAS_ActvACILvl2Sta 0 "INIT" 1 "INACTIVE" 2 "ACTIVE35(ACTIVE)" 3 "RESERVED" 4 "RESERVED" 5 "RESERVED" 6 "RESERVED" 7 "RESERVED" 8 "RESERVED" 9 "RESERVED" 10 "RESERVED" 11 "RESERVED" 12 "RESERVED" 13 "RESERVED" 14 "RESERVED" 15 "RESERVED";
VAL_ 203 ADAS_StrAnglReqVal 0 "0x0x000~0x3FFF:Real Values" 16383 "0x0x000~0x3FFF:Real Values";
VAL_ 203 ADAS_ACIAnglTqRedcGainVal 0 "0x0x00~0xFA:Real Values" 250 "0x0x00~0xFA:Real Values" 251 "RESERVED" 252 "RESERVED" 253 "RESERVED" 254 "RESERVED" 255 "RESERVED";
VAL_ 203 FCA_ESA_ActvSta 0 "Inactive" 1 "Active" 2 "RESERVED" 3 "RESERVED";
VAL_ 203 FCA_ESA_TqBstGainVal 0 "0x0x00~0xFA:Real Values" 250 "0x0x00~0xFA:Real Values" 251 "RESERVED" 252 "RESERVED" 253 "RESERVED" 254 "RESERVED" 255 "RESERVED";
VAL_ 234 LKA_FAULT 0 "ok" 1 "lka fault";
VAL_ 272 LKA_MODE 1 "warning only" 2 "assist" 6 "off";
VAL_ 272 LKA_ICON 0 "hidden" 1 "grey" 2 "green" 3 "flashing green";
VAL_ 272 LKAS_ANGLE_ACTIVE 0 "off" 1 "not active" 2 "active";
VAL_ 282 HBA_SysOptSta 0 "None HBA Option (Default)" 1 "HBA Option" 2 "Reserved" 3 "Error indicator";
VAL_ 282 HBA_SysSta 0 "HBA Disable" 1 "HBA Enable & High Beam Off" 2 "HBA Enable & High Beam On" 3 "Reserved" 4 "Reserved" 5 "Reserved" 6 "Reserved" 7 "System Fail";
VAL_ 282 HBA_IndLmpReq 0 "HBA Indicator Lamp Off" 1 "HBA Indicator Lamp On" 2 "Reserved" 3 "Error indicator";
VAL_ 282 FCA_Equip_MFC 0 "No Coding" 1 "Sensor Fusion FCA" 2 "Camera only FCA" 3 "No FCA Option" 4 "ADAS_DRV Option" 5 "Reserved" 6 "Not used" 7 "Error indicator";
VAL_ 282 HBA_OptUsmSta 0 "None HBA Option (Default)" 1 "HBA Function Off" 2 "HBA Function On" 3 "Invalid (Fail)";
VAL_ 282 DAW_LVDA_PUDis 0 "Default" 1 "Display “Leading vehicle departure alert”" 2 "Reserved" 3 "Error indicator";
VAL_ 282 DAW_LVDA_OptUsmSta 0 "No Option (default)" 1 "Off" 2 "On" 3 "Error Indicator";
VAL_ 282 DAW_OptUsmSta 0 "None DAW Option (Default)" 1 "System Off" 2 "System On" 3 "Reserved" 4 "Reserved" 5 "Reserved" 6 "Reserved" 7 "Invalid (Gray)";
VAL_ 282 DAW_SysSta 0 "System Off" 1 "Attention Level  1" 2 "Attention Level  2" 3 "Attention Level  3" 4 "Attention Level  4" 5 "Attention Level  5" 6 "Reserved" 7 "Reserved" 8 "Reserved" 9 "Reserved" 10 "Reserved" 11 "Reserved" 12 "Reserved" 13 "Reserved" 14 "System Standby" 15 "System Fail";
VAL_ 282 DAW_WrnMsgSta 0 "No Warning" 1 "Rest Recommend Warning" 2 "Hands-Off TMS call request" 3 "Reserved" 4 "Reserved" 5 "Reserved" 6 "Reserved" 7 "Error indicator";
VAL_ 282 DAW_TimeRstReq 0 "No signal" 1 "Time reset" 2 "Reserved" 3 "Error indicator";
VAL_ 282 DAW_SnstvtyModRetVal 0 "Default" 1 "Late" 2 "Normal" 3 "Reserved" 4 "Reserved" 5 "Reserved" 6 "Reserved" 7 "Invalid";
VAL_ 282 FR_CMR_SCCEquipSta 0 "Not Applied" 1 "Applied" 2 "Not used" 3 "Error Indicator";
VAL_ 298 LKA_MODE 1 "warning only" 2 "assist" 6 "off";
VAL_ 298 LKA_ICON 0 "hidden" 1 "grey" 2 "green" 3 "flashing green";
VAL_ 304 PARK_BUTTON 1 "Pressed" 2 "Not Pressed";
VAL_ 304 KNOB_POSITION 1 "R" 2 "N (on R side)" 3 "Centered" 4 "N (on D side)" 5 "D";
VAL_ 304 GEAR 1 "P" 2 "R" 3 "N" 4 "D";
VAL_ 352 AEB_SETTING 1 "off" 2 "warning only" 3 "active assist";
VAL_ 353 FCA_ICON 0 "HIDDEN" 1 "ORANGE" 2 "RED";
VAL_ 353 FCA_ALT_ICON 0 "HIDDEN" 1 "ORANGE" 3 "RED";
VAL_ 353 LKA_ICON 0 "HIDDEN" 1 "ORANGE" 3 "GRAY" 4 "GREEN";
VAL_ 353 HBA_ICON 0 "HIDDEN" 1 "GRAY" 2 "GREEN";
VAL_ 353 FCA_IMAGE 0 "HIDDEN" 2 "VISIBLE";
VAL_ 353 BCA_LEFT 0 "HIDDEN" 1 "VISIBLE" 2 "VISIBLE+ICON";
VAL_ 353 BCA_RIGHT 0 "HIDDEN" 1 "VISIBLE" 2 "VISIBLE+ICON";
VAL_ 353 LCA_LEFT_ARROW 0 "HIDDEN" 1 "VISIBLE";
VAL_ 353 LCA_RIGHT_ARROW 0 "HIDDEN" 1 "VISIBLE";
VAL_ 353 CENTERLINE 0 "HIDDEN" 1 "GREEN";
VAL_ 353 TARGET 0 "HIDDEN" 1 "BLUE" 3 "WHITE";
VAL_ 353 LANELINE_LEFT 0 "GRAY" 1 "HIDDEN" 2 "WHITE" 4 "ORANGE" 6 "GREEN";
VAL_ 353 LANELINE_RIGHT 0 "GRAY" 1 "HIDDEN" 2 "WHITE" 4 "ORANGE" 6 "GREEN";
VAL_ 353 LANE_HIGHLIGHT 0 "HIDDEN" 1 "GREEN" 2 "WHITE" 3 "BLUE" 4 "ORANGE" 5 "RED";
VAL_ 353 LANE_LEFT 0 "HIDDEN" 1 "GREEN";
VAL_ 353 LANE_RIGHT 0 "HIDDEN" 1 "GREEN";
VAL_ 353 LANE_ZOOM 0 "ZOOM" 1 "HIDDEN";
VAL_ 353 ALERTS_1 0 "HIDDEN" 1 "WARNING_ONLY_CAR_CENTER" 2 "WARNING_ONLY_CAR_LEFT" 3 "WARNING_ONLY_CAR_RIGHT" 4 "WARNING_ONLY_LEFT" 5 "WARNING_ONLY_RIGHT" 11 "EMERGENCY_BRAKING_CAR_CENTER" 12 "EMERGENCY_BRAKING_CAR_LEFT" 13 "EMERGENCY_BRAKING_CAR_RIGHT" 14 "EMERGENCY_BRAKING_LEFT" 15 "EMERGENCY_BRAKING_RIGHT" 21 "EMERGENCY_STEERING_CAR_LEFT" 22 "EMERGENCY_STEERING_CAR_RIGHT" 23 "EMERGENCY_STEERING_CAR_LEFT_AWAY" 24 "EMERGENCY_STEERING_CAR_RIGHT_AWAY" 25 "EMERGENCY_STEERING_REAR_LEFT" 26 "EMERGENCY_STEERING_REAR_RIGHT" 33 "DRIVE_CAREFULLY";
VAL_ 353 ALERTS_2 0 "HIDDEN" 1 "KEEP_HANDS_ON_STEERING_WHEEL" 2 "KEEP_HANDS_ON_STEERING_WHEEL_RED" 3 "LANE_FOLLOWING_ASSIST_DEACTIVATED" 4 "HIGHWAY_DRIVING_ASSIST_DEACTIVATED" 5 "CONSIDER_TAKING_A_BREAK" 6 "PRESS_OK_BUTTON_TO_ENABLE_LANE_CHANGE_ASSIST" 7 "COLLISION_RISK_VEHICLE_TAKING_EMERGENCY_CONTROL" 8 "TAKE_CONTROL_OF_THE_VEHICLE_IMMEDIATELY_VEHICLE_IS_STOPPING" 9 "TAKE_CONTROL_OF_THE_VEHICLE_IMMEDIATELY" 11 "HIGHWAY_DRIVING_PILOT_SYSTEM_DEACTIVATED_AUDIBLE" 12 "KEEP_YOUR_EYES_ON_THE_ROAD" 13 "HIGHWAY_DRIVING_PILOT_CONDITIONS_NOT_MET_AUDIBLE" 14 "COLLISION_RISK_VEHICLE_TAKING_EMERGENCY_CONTROL" 15 "SET_THE_WIPER_AND_LIGHT_CONTROLS_TO_AUTO" 16 "BE_PREPARED_TO_TAKE_CONTROL_OF_THE_VEHICLE_AT_ANY_TIME" 21 "TAKE_CONTROL_OF_THE_VEHICLE_IMMEDIATELY_VEHICLE_IS_STOPPING" 10 "TAKE_CONTROL_OF_THE_VEHICLE_IMMEDIATELY";
VAL_ 353 ALERTS_3 1 "AUTOMATICALLY_ADJUSTING_TO_THE_POSTED_SPEED_LIMIT" 2 "SET_SPEED_CHANGED" 3 "AUTOMATICALLY_ADJUSTING_TO_THE_POSTED_SPEED_LIMIT" 4 "SET_SPEED_CHANGED" 7 "DISTANCE_1" 8 "DISTANCE_2" 9 "DISTANCE_3" 10 "DISTANCE_4" 17 "DRIVE_CAREFULLY" 18 "CHECK_SURROUNDINGS" 19 "CONDITIONS_NOT_MET" 20 "LANES_NOT_DETECTED" 21 "CURVE_TOO_SHARP" 22 "LANE_TOO_NARROW" 23 "ROAD_TYPE_NOT_SUPPORTED" 24 "UNAVAILABLE_WITH_HAZARD_LIGHTS_ON" 25 "VEHICLE_SPEED_IS_TOO_LOW" 26 "KEEP_HANDS_ON_STEERING_WHEEL" 27 "LANE_TYPE_NOT_SUPPORTED" 28 "LANE_ASSIST_CANCELED_STEERING_INPUT_DETECTED" 0 "HIDDEN";
VAL_ 353 ALERTS_4 0 "HIDDEN" 1 "TAKE_FOOT_OFF_THE_ACCELERATOR_PEDAL" 2 "TAKE_FOOT_OFF_THE_BRAKE_PEDAL" 3 "UNAVAILABLE_WHILE_HIGHWAY_DRIVING_PILOT_SYSTEM_IS_ACTIVE" 4 "TO_EXIT_HDP_GRASP_THE_STEERING_WHEEL_THEN_PRESS_AND_HOLD_THE_HDP_BUTTON" 5 "ACCELERATOR_PEDAL_OPERATION_LIMITED_FOR_SAFETY" 6 "TURN_OFF_HAZARD_WARNING_LIGHTS_AND_TURN_SIGNAL" 7 "KEEP_THE_DRIVERS_SEAT_IN_A_SAFE_DRIVING_POSITION" 16 "SET_SPEED_CHANGED" 17 "ACTIVATING_WINDSHIELD_DEFOG_TO_MAINTAIN_THE_DRIVERS_VIEW" 18 "SET_THE_WIPER_AND_LIGHT_CONTROLS_TO_AUTO" 19 "VEHICLE_SPEED_REDUCED_FOR_SAFETY_MERGING_LANES_AHEAD" 20 "SPEED_REDUCED_FOR_SAFETY_CONSTRUCTION_ZONE_DETECTED" 21 "VEHICLE_SPEED_LIMITED_SENSOR_DETECTION_RANGE_LIMITED" 22 "PREPARE_TO_TAKE_CONTROL_UNSUPPORTED_ROAD_TYPE_AHEAD" 23 "PREPARE_TO_TAKE_CONTROL_ENTRANCE_AND_EXIT_RAMPS_AHEAD" 24 "PREPARE_TO_TAKE_CONTROL_TOLLGATE_AHEAD" 25 "PREPARE_TO_TAKE_CONTROL_ROAD_EVENT_AHEAD" 26 "CLEARING_PATH_FOR_EMERGENCY_VEHICLE" 27 "VEHICLE_IS_TOO_SLOW_COMPARED_TO_TRAFFIC_FLOW" 28 "AFTER_SUNSET_HDP_IS_AVAILABLE_IN_AN_INSIDE_LANE_BEHIND_A_LEADING_VEHICLE" 29 "VEHICLE_SPEED_LIMITED_MERGING_LANES_AHEAD" 30 "VEHICLE_SPEED_LIMITED_CONSTRUCTION_ZONE_DETECTED" 31 "VEHICLE_SPEED_TEMPORARILY_LIMITED_FOR_SAFETY" 32 "PRESS_AND_HOLD_THE_BUTTON_TO_ACTIVATE_HIGHWAY_DRIVING_PILOT" 40 "HIGHWAY_DRIVING_PILOT_SYSTEM_IS_AVAILABLE" 64 "RESTART_VEHICLE_AFTER_EMERGENCY_STOP" 65 "CONNECTED_SERVICES_UNAVAILABLE" 66 "AVAILABLE_AFTER_VEHICLE_SOFTWARE_IS_UPDATED" 67 "ROAD_TYPE_NOT_SUPPORTED" 68 "ONLY_AVAILABLE_WHILE_DRIVING_ON_HIGHWAY_LANES" 69 "UNAVAILABLE_WHILE_OTHER_WARNINGS_ARE_ACTIVE" 70 "CANNOT_ACTIVATE_AT_ENTRANCE_EXIT_RAMPS" 71 "LANE_UNSUPPORTED" 72 "NOT_AVAILABLE_IN_THIS_COUNTRY" 79 "CHECKING_THE_DETECTION_RANGE_OF_THE_SENSOR" 80 "SHIFT_TO_D" 81 "ENGINE_STOPPED_BY_AUTO_STOP" 82 "INCREASE_DISTANCE_FROM_VEHICLE_AHEAD" 83 "VEHICLE_SPEED_IS_TOO_HIGH" 84 "CENTER_VEHICLE_IN_THE_LANE" 85 "PARKING_ASSIST_IS_ACTIVE" 86 "ESC_ACTIVIATION_REQUIRED" 87 "UNFOLD_SIDE_VIEW_MIRRORS" 88 "UNAVAILABLE_IN_THE_OUTER_LANE_AFTER_SUNSET" 89 "VEHICLE_SPEED_LIMITED_AFTER_SUNSET_FOR_SAFETY" 90 "LEADING_VEHICLE_NOT_DETECTED" 104 "AGGRESSIVE_BRAKING_OR_STEERING_DETECTED" 110 "SENSOR_AUTO_CALIBRATION_IN_PROGRESS_THIS_MAY_TAKE_SEVERAL_MINUTES" 111 "HIGHWAY_DRIVING_PILOT_WILL_BE_AVAILABLE_SHORTLY" 112 "IF_STEERING_WHEEL_IS_USED_HDP_WILL_BE_DEACTIVATED" 120 "IMPACT_DETECTED" 128 "UNSUITABLE_USE_OF_ACCELERATOR_PEDAL_DETECTED" 129 "GEAR_SHIFTER_USE_DETECTED" 130 "UNSUITABLE_BRAKE_PEDAL_USE_DETECTED" 131 "VEHICLE_START_BUTTON_PRESSED" 132 "VEHICLE_HAS_BEEN_STOPPED_FOR_TOO_LONG" 141 "TRAFFIC_CONGESTION_HAS_CLEARED" 142 "ENTRANCE_AND_EXIT_RAMPS_AHEAD" 143 "UNSUPPORTED_LANE_AHEAD" 144 "UNSUPPORTED_ROAD_TYPE_AHEAD" 145 "LANE_DEPARTURE_DETECTED" 146 "MAXIMUM_SPEED_EXCEEDED" 147 "HIGHWAY_DRIVING_PILOT_LIMITED_ABNORMAL_VEHICLE_CONTROLLER_STATUS" 148 "WIPER_LIGHT_CONTROL_SETTINGS_ARE_UNSUITABLE_FOR_USE_WITH_HDP" 149 "WINDSHIELD_DEFOG_SYSTEM_STATUS_IS_UNSUITABLE_FOR_USE_WITH_HDP" 150 "HAZARD_WARNING_LIGHTS_OR_TURN_SIGNAL_OPERATION_DETECTED" 151 "PERFORMING_EVASIVE_STEERING_OBSTACLES_DETECTED_AHEAD" 152 "HIGHWAY_DRIVING_PILOT_LIMITED_SENSOR_DETECTION_RANGE_LIMITED" 160 "CHECK_HIGHWAY_DRIVING_PILOT_SYSTEM" 161 "SAFETY_FUNCTION_ACTIVATED" 176 "CAMERA_OBSCURED" 177 "RADAR_BLOCKED" 178 "LIDAR_BLOCKED" 179 "AIRBAG_WARNING_LIGHT_IS_ON" 180 "ATTACHED_TRAILED_DETECTED" 181 "HIGH_OUTSIDE_TEMPERATURE" 182 "LOW_OUTSIDE_TEMPERATURE" 190 "UNAVAILABLE_DUE_TO_THE_ROAD_EVENT_INFORMATION_RECEIVED" 191 "UNAVAILABLE_NEAR_TOLLGATES" 192 "DRIVERS_SEAT_IS_NOT_IN_A_SAFE_DRIVING_POSITION" 193 "VEHICLE_DRIVING_THE_WRONG_WAY_DETECTED_AHEAD" 194 "EMERGENCY_VEHICLE_DETECTED" 195 "OBSTACLE_DETECTED_AHEAD" 196 "SENSOR_BLOCKED_DUE_TO_RAIN_SNOW_OR_ROAD_DEBRIS" 197 "SLIPPERY_ROAD_SURFACE_DETECTED" 198 "CONSTRUCTION_ZONE_DETECTED_AHEAD" 199 "PEDESTRIAN_DETECTED_AHEAD" 200 "UNSUITABLE_DRIVERS_SEAT_POSITION_DETECTED" 201 "FOLDED_SIDE_VIEW_MIRRORS_DETECTED" 208 "VEHICLE_POSITION_NOT_DETECTED" 209 "LANE_NOT_DETECTED" 210 "DRIVER_NOT_DETECTED" 211 "KEEP_YOUR_EYES_ON_THE_ROAD" 212 "LEADING_VEHICLE_REQUIRED_AFTER_SUNSET" 213 "TBD" 240 "LOW_FUEL" 241 "LOW_TIRE_PRESSURE" 242 "DOOR_OPEN" 243 "TRUNK_OPEN" 244 "HOOD_OPEN" 245 "SEAT_BELT_NOT_FASTENED" 246 "PARKING_BRAKE_ACTIVATED" 247 "LOW_EV_BATTERY" 248 "HDP_DEACTIVATION_DELAYED_RISK_OF_COLLISION_DETECTED" 249 "LIFTGATE_OPENED";
VAL_ 353 ALERTS_5 0 "HIDDEN" 1 "DRIVERS_GRASP_NOT_DETECTED_DRIVING_SPEED_WILL_BE_LIMITED" 2 "WATCH_FOR_SURROUNDING_VEHICLES" 3 "SMART_CRUISE_CONTROL_DEACTIVATED" 4 "SMART_CRUISE_CONTROL_CONDITIONS_NOT_MET" 5 "USE_SWITCH_OR_PEDAL_TO_ACCELERATE" 6 "DRIVER_ASSISTNCE_SYSTEM_LIMITED_TRAILER_ATTACHED" 7 "DRIVER_ASSISTNCE_SYSTEM_LIMITED_DRIVER_FULL_FACE_NOT_VISIBLE" 11 "LEADING_VEHICLE_IS_DRIVING_AWAY" 12 "STOP_VEHICLE_THEN_TRY_AGAIN" 19 "ACTIVATING_HIGHWAY_DRIVING_PILOT_SYSTEM" 20 "CONTINUING_USE_OF_HIGHWAY_DRIVING_PILOT_WILL_RESULT_IN_DEVIATION_FROM_THE_NAVIGATION_ROUTE" 21 "HIGHWAY_DRIVING_PILOT_SYSTEM_DEACTIVATED_SILENT" 22 "HIGHWAY_DRIVING_PILOT_SYSTEM_NOT_APPLIED" 23 "HIGHWAY_DRIVING_PILOT_CONDITIONS_NOT_MET_SILENT";
VAL_ 353 MUTE 0 "NONE" 1 "MUTED";
VAL_ 353 SOUNDS_1 0 "NONE" 3 "FAST BEEP" 6 "CONSTANT BEEP";
VAL_ 353 SOUNDS_2 0 "NONE" 2 "SINGLE CHIME" 3 "CONSTANT CHIME" 6 "FAST BEEP";
VAL_ 353 SOUNDS_3 0 "NONE" 3 "SOFT CHIME" 5 "SINGLE CHIME";
VAL_ 353 SOUNDS_4 0 "NONE" 2 "DOUBLE CHIME";
VAL_ 353 SETSPEED_HUD 0 "HIDDEN" 1 "GRAY" 2 "GREEN" 3 "WHITE" 5 "CYAN";
VAL_ 353 DISTANCE_LEAD 0 "HIDDEN" 1 "GRAY" 2 "WHITE";
VAL_ 353 DISTANCE_CAR 0 "HIDDEN" 1 "GRAY" 2 "WHITE" 3 "CYAN A";
VAL_ 353 DISTANCE_SPACING 0 "HIDDEN" 1 "BLUE" 3 "WHITE" 5 "CYAN";
VAL_ 353 SETSPEED 0 "HIDDEN" 1 "GRAY" 2 "GREEN" 3 "WHITE" 6 "CYAN";
VAL_ 353 HDA_ICON 0 "HIDDEN" 1 "GRAY" 2 "GREEN" 3 "WHITE" 5 "CYAN HDP";
VAL_ 353 SLA_ICON 0 "HIDDEN" 1 "WHITE UP" 2 "WHITE DOWN" 3 "GREEN UP" 4 "GREEN DOWN";
VAL_ 353 NAV_ICON 0 "HIDDEN" 1 "GRAY" 2 "GREEN" 4 "WHITE";
VAL_ 353 LFA_ICON 0 "HIDDEN" 1 "GRAY" 2 "GREEN" 3 "WHITE" 5 "CYAN";
VAL_ 353 LCA_LEFT_ICON 0 "HIDDEN" 1 "GRAY" 2 "GREEN" 4 "WHITE";
VAL_ 353 LCA_RIGHT_ICON 0 "HIDDEN" 1 "GRAY" 2 "GREEN" 4 "WHITE";
VAL_ 353 BACKGROUND 0 "HIDDEN" 1 "BLUE" 3 "ORANGE" 4 "FLASHING ORANGE" 6 "FLASHING RED" 7 "GRAY";
VAL_ 353 DAW_ICON 0 "HIDDEN" 1 "ORANGE";
VAL_ 353 CAR_CIRCLE 0 "HIDDEN" 1 "GRAY" 2 "CYAN";
VAL_ 354 COUNTRY 0 "HIDDEN" 1 "SOUTH_KOREA" 4 "INTL" 5 "JAPAN" 6 "CANADA" 7 "USA" 8 "CHINA" 9 "INTL";
VAL_ 354 SPEEDLIMIT_FLASH 0 "HIDDEN" 1 "ERROR" 2 "NORMAL" 4 "RED";
VAL_ 354 SIGNS 0 "HIDDEN" 1 "PEDESTRIAN_CROSSING" 2 "SCHOOL_CROSSWALK" 8 "STOP" 9 "YIELD" 16 "DO_NOT_PASS" 19 "DO_NOT_ENTER" 24 "ROUNDABOUT" 26 "RIGHT_CURVE_AHEAD" 27 "LEFT_CURVE_AHEAD" 28 "SLIGHT_RIGHT_CURVE_AHEAD" 29 "SLIGHT_LEFT_CURVE_AHEAD";
VAL_ 354 SPEEDLIMIT_WEATHER 0 "HIDDEN" 1 "RAIN" 2 "SNOW" 3 "RAIN+SNOW" 4 "TRAILER";
VAL_ 354 VIBRATE 0 "NONE" 1 "VIBRATE";
VAL_ 354 LEAD 0 "HIDDEN" 1 "GRAY BOX" 2 "WHITE BOX" 3 "GRAY CAR" 4 "WHITE CAR" 5 "GRAY TRUCK" 6 "WHITE TRUCK" 7 "GRAY PERSON" 8 "WHITE PERSON" 9 "GRAY BICYCLE" 10 "WHITE BICYCLE" 11 "GRAY MOTORCYCLE" 12 "WHITE MOTORCYCLE" 13 "DARK CONE" 14 "ORANGE CONE";
VAL_ 354 LEAD_ALT 0 "HIDDEN" 1 "GRAY BOX" 2 "WHITE BOX" 3 "DIM CONE" 4 "ORANGE CONE";
VAL_ 354 LEAD_LEFT 0 "HIDDEN" 1 "GRAY BOX" 2 "WHITE BOX" 3 "GRAY CAR" 4 "WHITE CAR" 5 "GRAY TRUCK" 6 "WHITE TRUCK" 7 "GRAY PERSON" 8 "WHITE PERSON" 9 "GRAY BICYCLE" 10 "WHITE BICYCLE" 11 "GRAY MOTORCYCLE" 12 "WHITE MOTORCYCLE" 13 "DARK CONE" 14 "ORANGE CONE";
VAL_ 354 LEAD_RIGHT 0 "HIDDEN" 1 "GRAY BOX" 2 "WHITE BOX" 3 "GRAY CAR" 4 "WHITE CAR" 5 "GRAY TRUCK" 6 "WHITE TRUCK" 7 "GRAY PERSON" 8 "WHITE PERSON" 9 "GRAY BICYCLE" 10 "WHITE BICYCLE" 11 "GRAY MOTORCYCLE" 12 "WHITE MOTORCYCLE" 13 "DARK CONE" 14 "ORANGE CONE";
VAL_ 354 FAULT_FSS 0 "HIDDEN" 1 "CHECK_FORWARD_SAFETY_SYSTEM" 2 "FORWARD_SAFETY_SYSTEM_LIMITED_CAMERA_OBSCURED" 3 "FORWARD_SAFETY_SYSTEM_LIMITED_RADAR_BLOCKED";
VAL_ 354 FAULT_FCA 0 "HIDDEN" 1 "CHECK_FORWARD_SIDE_SAFETY_SYSTEM" 2 "FORWARD_SIDE_SAFETY_SYSTEM_LIMITED_CAMERA_OBSCURED" 3 "FORWARD_SIDE_SAFETY_SYSTEM_LIMITED_RADAR_BLOCKED";
VAL_ 354 FAULT_LSS 0 "HIDDEN" 1 "CHECK_LANE_SAFETY_SYSTEM" 2 "LANE_SAFETY_SYSTEM_DISABLED_CAMERA_OBSCURED";
VAL_ 354 FAULT_SLA 0 "HIDDEN" 1 "CHECK_SPEED_LIMIT_SYSTEM" 2 "SPEED_LIMIT_SYSTEM_DISABLED_CAMERA_OBSCURED";
VAL_ 354 FAULT_DAW 0 "HIDDEN" 1 "CHECK_INATTENTIVE_DRIVING_WARNING_SYSTEM" 2 "INATTENTIVE_DRIVING_WARNING_SYSTEM_DISABLED_CAMERA_OBSCURED";
VAL_ 354 FAULT_HBA 0 "HIDDEN" 1 "CHECK_HIGH_BEAM_ASSIST_SYSTEM";
VAL_ 354 FAULT_SCC 0 "HIDDEN" 1 "CHECK_SMART_CRUISE_CONTROL_SYSTEM" 2 "SMART_CRUISE_CONTROL_DISABLED_RADAR_BLOCKED";
VAL_ 354 FAULT_LFA 0 "HIDDEN" 1 "CHECK_LANE_FOLLOWING_SYSTEM_ASSIST_SYSTEM";
VAL_ 354 FAULT_HDA 0 "HIDDEN" 1 "CHECK_HIGHWAY_DRIVING_ASSIST_SYSTEM";
VAL_ 354 FAULT_LCA 0 "HIDDEN" 1 "CHECK_LANE_CHANGE_ASSIST_FUNCTION" 2 "LANE_CHANGE_ASSIST_FUNCTION_DISABLED_CAMERA_OBSCURED" 3 "LANE_CHANGE_ASSIST_FUNCTION_DISABLED_RADAR_BLOCKED";
VAL_ 354 FAULT_HDP 0 "HIDDEN" 1 "CHECK_HIGHWAY_DRIVING_PILOT_SYSTEM" 2 "HIGHWAY_DRIVING_PILOT_DISABLED_CAMERA_OBSCURED" 3 "HIGHWAY_DRIVING_PILOT_DISABLED_RADAR_BLOCKED" 4 "HIGHWAY_DRIVING_PILOT_DISABLED_LIDAR_BLOCKED";
VAL_ 354 FAULT_DAS 0 "HIDDEN" 1 "CHECK_DRIVER_ASSISTANCE_SYSTEM" 2 "DRIVER_ASSISTANCE_SYSTEM_LIMITED_CAMERA_OBSCURED" 3 "DRIVER_ASSISTANCE_SYSTEM_LIMITED_RADAR_BLOCKED" 4 "DRIVER_ASSISTANCE_SYSTEM_LIMITED_CAMERA_OBSCURED_AND_RADAR_BLOCKED";
VAL_ 354 FAULT_ESS 0 "HIDDEN" 1 "CHECK_EMERGENCY_STOPPING_FUNCTION" 2 "EMERGENCY_STOPPING_FUNCTION_DISABLED_CAMERA_OBSCURED" 3 "EMERGENCY_STOPPING_FUNCTION_DISABLED_RADAR_BLOCKED";
VAL_ 362 BLINKER_CONTROL 1 "hazards" 2 "hazards button backlight" 3 "left blinkers" 4 "right blinkers";
VAL_ 373 ACCEnable 0 "SCC ready" 1 "SCC temp fault" 2 "SCC permanent fault" 3 "SCC permanent fault, communication issue";
VAL_ 416 ACCMode 0 "off" 1 "enabled" 2 "driver_override" 3 "off_maybe_fault" 4 "cancelled";
VAL_ 426 CRUISE_BUTTONS 0 "none" 1 "res_accel" 2 "set_decel" 3 "gap_distance" 4 "pause_resume";
VAL_ 437 Info_LftLnQualSta 0 "Very Low Quality" 1 "Low Quality" 2 "High Quality" 3 "Very High Quality" 4 "Reserved" 5 "Reserved" 6 "Reserved" 7 "Error indicator";
VAL_ 437 Info_LftLnDptSta 0 "No Left Line Departure" 1 "Left Line Departure" 2 "Reserved" 3 "Error Indicator";
VAL_ 437 Info_RtLnQualSta 0 "Very Low Quality" 1 "Low Quality" 2 "High Quality" 3 "Very High Quality" 4 "Reserved" 5 "Reserved" 6 "Reserved" 7 "Error indicator";
VAL_ 437 Info_RtLnDptSta 0 "No Right Line Departure" 1 "Right Line Departure" 2 "Reserved" 3 "Error Indicator";
VAL_ 437 Info_RtLnCvtrVal 65534 "Reserved" 65535 "Error indicator";
VAL_ 463 CRUISE_BUTTONS 0 "none" 1 "res_accel" 2 "set_decel" 3 "gap_distance" 4 "pause_resume";
VAL_ 463 RIGHT_PADDLE 0 "Not Pulled" 1 "Pulled";
VAL_ 463 LEFT_PADDLE 0 "Not Pulled" 1 "Pulled";
VAL_ 506 ISLW_OptUsmSta 0 "None ISLW Option (Default)" 1 "System Disabled by USM" 2 "System Enable by USM" 3 "Invalid";
VAL_ 506 ISLW_SysSta 0 "Normal (Default)" 1 "System Fail" 2 "ISLW Temporary Unavailable" 3 "Reserved";
VAL_ 506 ISLW_NoPassingInfoDis 0 "None Display (Default)" 1 "LHD No Passing Zone Display" 2 "RHD No Passing Zone Display" 3 "Reserved" 4 "Reserved" 5 "Reserved" 6 "Reserved" 7 "Invalid";
VAL_ 506 ISLW_OvrlpSignDis 0 "None (Default)" 1 "Overlap Sign" 2 "Reserved" 3 "Error indicator";
VAL_ 506 ISLW_SpdCluMainDis 0 "No Recognition (Default)" 253 "Unlimited Speed" 254 "Reserved" 255 "Invalid";
VAL_ 506 ISLW_SpdNaviMainDis 0 "No Recognition (Default)" 253 "Unlimited Speed" 254 "Reserved" 255 "Invalid";
VAL_ 506 ISLW_SubCondinfoSta1 0 "None (Default)" 1 "Rain" 2 "Snow" 3 "Snow&Rain" 4 "Trailer" 5 "Reserved" 6 "Reserved" 7 "Reserved" 8 "Reserved" 9 "Reserved" 10 "Reserved" 11 "Reserved" 12 "Reserved" 13 "Reserved" 14 "Generic" 15 "Invalid";
VAL_ 506 ISLW_SubCondinfoSta2 0 "None (Default)" 1 "Rain" 2 "Snow" 3 "Snow&Rain" 4 "Trailer" 5 "Reserved" 6 "Reserved" 7 "Reserved" 8 "Reserved" 9 "Reserved" 10 "Reserved" 11 "Reserved" 12 "Reserved" 13 "Reserved" 14 "Generic" 15 "Invalid";
VAL_ 506 ISLW_SpdCluSubMainDis 0 "No Recognition (Default)" 253 "Unlimited Speed" 254 "Reserved" 255 "Invalid";
VAL_ 506 ISLW_SpdCluDisSubCond1 0 "No Recognition (Default)" 253 "LHD Conditional No Passing ZONE" 254 "RHD Conditional No Passing ZONE" 255 "Invalid";
VAL_ 506 ISLW_SpdCluDisSubCond2 0 "No Recognition (Default)" 253 "LHD Conditional No Passing ZONE" 254 "RHD Conditional No Passing ZONE" 255 "Invalid";
VAL_ 506 ISLW_SpdNaviSubMainDis 0 "No Recognition (Default)" 253 "Unlimited Speed" 254 "Reserved" 255 "Invalid";
VAL_ 506 ISLW_SpdNaviDisSubCond1 0 "No Recognition (Default)" 253 "LHD Conditional No Passing ZONE" 254 "RHD Conditional No Passing ZONE" 255 "Invalid";
VAL_ 506 ISLW_SpdNaviDisSubCond2 0 "No Recognition (Default)" 253 "LHD Conditional No Passing ZONE" 254 "RHD Conditional No Passing ZONE" 255 "Invalid";
VAL_ 506 ISLA_SpdwOffst 0 "No Recognition" 253 "Unlimited Speed" 254 "Reserved" 255 "Invalid";
VAL_ 506 ISLA_SwIgnoreReq 0 "Allow All Switch Inputs (default)" 1 "-(SET) Switch Input Ignore" 2 "+(SET) Switch Input Ignore" 3 "-(SET) & +(SET) Switch Inputs Ignore";
VAL_ 506 ISLA_SpdChgReq 0 "Default" 1 "Speed Change Request" 2 "Reserved" 3 "Reserved";
VAL_ 506 ISLA_SpdWrn 0 "No Warning" 1 "Warning" 2 "Reserved" 3 "Reserved";
VAL_ 506 ISLA_IcyWrn 0 "No Warning" 1 "Warning" 2 "Reserved" 3 "Reserved";
VAL_ 506 ISLA_SymFlashMod 0 "No Flasing" 1 "Flashing Sign" 2 "Flashing - Arrow Symbol" 3 "Flashing + Arrow Symbol" 4 "Flashing Auto Symbol" 5 "Reserved" 6 "Reserved" 7 "Reserved";
VAL_ 506 ISLA_Popup 0 "No Popup" 1 "MSLA Speed will Change" 2 "MSLA Speed has Changed" 3 "CC_SCC Speed will Change" 4 "CC_SCC Speed has Changed" 5 "Reserved" 6 "Reserved" 7 "Reserved";
VAL_ 506 ISLA_OptUsmSta 0 "None ISLA Option (속도 제한 메뉴 삭제)" 1 "Off" 2 "Warning" 3 "Assist" 4 "Reserved" 5 "Reserved" 6 "Reserved" 7 "Invalid (GRAY)";
VAL_ 506 ISLA_OffstUsmSta 0 "None Offset Function" 1 "-10kph or -5mph" 2 "-5kph or -3mph" 3 "0kph or 0mph" 4 "+5kph or +3mph" 5 "+10kph or +5mph" 6 "Reserved" 7 "Invalid (GRAY)";
VAL_ 506 ISLA_AutoUsmSta 0 "None Auto Function (Delete Menu)" 1 "Auto Off" 2 "Auto On" 3 "Invalid (GRAY)";
VAL_ 506 ISLA_Cntry 0 "Europe/Russia/Australia" 1 "Domestic" 2 "China" 3 "USA" 4 "Canada" 5 "Australia" 6 "Reserved" 7 "Reserved" 8 "Reserved" 9 "Reserved" 10 "Reserved" 11 "Reserved" 12 "Reserved" 13 "Reserved" 14 "Reserved" 15 "Initial Value (default)";
VAL_ 506 ISLA_AddtnlSign 0 "No Recognition (default)" 1 "School Crossing" 16 "Do Not Pass" 17 "Reserved" 18 "Reserved" 19 "Reserved" 20 "Reserved" 21 "Reserved" 22 "Reserved" 23 "Reserved" 24 "Exit" 25 "Roundabout" 26 "Right Curve" 27 "Left Curve" 28 "Winding Road" 29 "Reserved" 30 "Reserved" 31 "Reserved" 2 "Pedestrian Crossing" 3 "Bicycle Crossing" 4 "Reserved" 5 "Reserved" 6 "Reserved" 7 "Reserved" 8 "Stop" 9 "Yield" 10 "Stop Ahead" 11 "Yield Ahead" 12 "Road Construction Ahead" 13 "Lane Reduction" 14 "Reserved" 15 "Reserved";
VAL_ 506 ISLA_SchoolZone 0 "No School Zone" 1 "School Zone" 2 "Reserved" 3 "Reserved";
VAL_ 687 HOD_Dir_Status 0 "HANDS OFF" 1 "HAND TOUCH (SOFT)" 2 "HAND TOUCH (STRONG)" 3 "HAND GRIP (SOFT)" 4 "HAND GRIP (STRONG)" 5 "RESERVED" 6 "RESERVED";
VAL_ 698 IFSref_FR_CMR_Sta 0 "None Option (Default)" 1 "Normal" 2 "Blockage Status" 3 "Error Indicator";
VAL_ 698 IFSref_VehNumVal 0 "No vehicle" 1 "Number of vehicles" 2 "Number of vehicles" 3 "Number of vehicles" 4 "Number of vehicles" 5 "Number of vehicles" 6 "Number of vehicles" 7 "Number of vehicles" 8 "Number of vehicles" 9 "Number of vehicles" 10 "Number of vehicles" 11 "Over than 10 vehicles" 12 "Reserved" 13 "Reserved" 14 "Default" 15 "Error indicator";
VAL_ 698 IFSref_ILLAmbtSta 0 "Bright" 1 "Dark" 2 "Not used" 3 "Error indicator";
VAL_ 698 IFSref_VehLftAngl1Val 501 "Not used" 502 "Not used" 503 "Not used" 504 "Not used" 505 "Not used" 506 "Not used" 507 "Not used" 508 "Not used" 509 "Not used" 510 "Default" 511 "Error indicator";
VAL_ 698 IFSref_VehRtAngl1Val 501 "Not used" 502 "Not used" 503 "Not used" 504 "Not used" 505 "Not used" 506 "Not used" 507 "Not used" 508 "Not used" 509 "Not used" 510 "Default" 511 "Error indicator";
VAL_ 698 IFSref_VehLftAngl2Val 501 "Not used" 502 "Not used" 503 "Not used" 504 "Not used" 505 "Not used" 506 "Not used" 507 "Not used" 508 "Not used" 509 "Not used" 510 "Default" 511 "Error indicator";
VAL_ 698 IFSref_VehDst1Val 0 "No Value" 1 "1~10m" 2 "11~20m" 3 "21~30m" 4 "31~40m" 5 "41~50m" 6 "51~60m" 7 "61~70m" 8 "71~80m" 9 "81~90m" 10 "91~100m" 11 "101~200m" 12 "201~300m" 13 "301~400m" 14 "401m~" 15 "Error indicator";
VAL_ 698 IFSref_VehRtAngl2Val 501 "Not used" 502 "Not used" 503 "Not used" 504 "Not used" 505 "Not used" 506 "Not used" 507 "Not used" 508 "Not used" 509 "Not used" 510 "Default" 511 "Error indicator";
VAL_ 698 IFSref_VehLftAngl3Val 501 "Not used" 502 "Not used" 503 "Not used" 504 "Not used" 505 "Not used" 506 "Not used" 507 "Not used" 508 "Not used" 509 "Not used" 510 "Default" 511 "Error indicator";
VAL_ 698 IFSref_VehRtAngl3Val 501 "Not used" 502 "Not used" 503 "Not used" 504 "Not used" 505 "Not used" 506 "Not used" 507 "Not used" 508 "Not used" 509 "Not used" 510 "Default" 511 "Error indicator";
VAL_ 698 IFSref_VehLftAngl4Val 501 "Not used" 502 "Not used" 503 "Not used" 504 "Not used" 505 "Not used" 506 "Not used" 507 "Not used" 508 "Not used" 509 "Not used" 510 "Default" 511 "Error indicator";
VAL_ 698 IFSref_VehRtAngl4Val 501 "Not used" 502 "Not used" 503 "Not used" 504 "Not used" 505 "Not used" 506 "Not used" 507 "Not used" 508 "Not used" 509 "Not used" 510 "Default" 511 "Error indicator";
VAL_ 698 IFSref_VehLftAngl5Val 501 "Not used" 502 "Not used" 503 "Not used" 504 "Not used" 505 "Not used" 506 "Not used" 507 "Not used" 508 "Not used" 509 "Not used" 510 "Default" 511 "Error indicator";
VAL_ 698 IFSref_VehRtAngl5Val 501 "Not used" 502 "Not used" 503 "Not used" 504 "Not used" 505 "Not used" 506 "Not used" 507 "Not used" 508 "Not used" 509 "Not used" 510 "Default" 511 "Error indicator";
VAL_ 698 IFSref_VehLftAngl6Val 501 "Not used" 502 "Not used" 503 "Not used" 504 "Not used" 505 "Not used" 506 "Not used" 507 "Not used" 508 "Not used" 509 "Not used" 510 "Default" 511 "Error indicator";
VAL_ 698 IFSref_VehRtAngl6Val 501 "Not used" 502 "Not used" 503 "Not used" 504 "Not used" 505 "Not used" 506 "Not used" 507 "Not used" 508 "Not used" 509 "Not used" 510 "Default" 511 "Error indicator";
VAL_ 698 IFSref_VehLftAngl7Val 501 "Not used" 502 "Not used" 503 "Not used" 504 "Not used" 505 "Not used" 506 "Not used" 507 "Not used" 508 "Not used" 509 "Not used" 510 "Default" 511 "Error indicator";
VAL_ 698 IFSref_VehRtAngl7Val 501 "Not used" 502 "Not used" 503 "Not used" 504 "Not used" 505 "Not used" 506 "Not used" 507 "Not used" 508 "Not used" 509 "Not used" 510 "Default" 511 "Error indicator";
VAL_ 698 IFSref_VehLftAngl8Val 501 "Not used" 502 "Not used" 503 "Not used" 504 "Not used" 505 "Not used" 506 "Not used" 507 "Not used" 508 "Not used" 509 "Not used" 510 "Default" 511 "Error indicator";
VAL_ 698 IFSref_VehRtAngl8Val 501 "Not used" 502 "Not used" 503 "Not used" 504 "Not used" 505 "Not used" 506 "Not used" 507 "Not used" 508 "Not used" 509 "Not used" 510 "Default" 511 "Error indicator";
VAL_ 698 IFSref_VehLftAngl9Val 501 "Not used" 502 "Not used" 503 "Not used" 504 "Not used" 505 "Not used" 506 "Not used" 507 "Not used" 508 "Not used" 509 "Not used" 510 "Default" 511 "Error indicator";
VAL_ 698 IFSref_VehRtAngl9Val 501 "Not used" 502 "Not used" 503 "Not used" 504 "Not used" 505 "Not used" 506 "Not used" 507 "Not used" 508 "Not used" 509 "Not used" 510 "Default" 511 "Error indicator";
VAL_ 698 IFSref_VehLftAngl10Val 501 "Not used" 502 "Not used" 503 "Not used" 504 "Not used" 505 "Not used" 506 "Not used" 507 "Not used" 508 "Not used" 509 "Not used" 510 "Default" 511 "Error indicator";
VAL_ 698 IFSref_VehRtAngl10Val 501 "Not used" 502 "Not used" 503 "Not used" 504 "Not used" 505 "Not used" 506 "Not used" 507 "Not used" 508 "Not used" 509 "Not used" 510 "Default" 511 "Error indicator";
VAL_ 698 IFSref_VehDst2Val 0 "No Value" 1 "1~10m" 2 "11~20m" 3 "21~30m" 4 "31~40m" 5 "41~50m" 6 "51~60m" 7 "61~70m" 8 "71~80m" 9 "81~90m" 10 "91~100m" 11 "101~200m" 12 "201~300m" 13 "301~400m" 14 "401m~" 15 "Error indicator";
VAL_ 698 IFSref_VehDst3Val 0 "No Value" 1 "1~10m" 2 "11~20m" 3 "21~30m" 4 "31~40m" 5 "41~50m" 6 "51~60m" 7 "61~70m" 8 "71~80m" 9 "81~90m" 10 "91~100m" 11 "101~200m" 12 "201~300m" 13 "301~400m" 14 "401m~" 15 "Error indicator";
VAL_ 698 IFSref_VehDst4Val 0 "No Value" 1 "1~10m" 2 "11~20m" 3 "21~30m" 4 "31~40m" 5 "41~50m" 6 "51~60m" 7 "61~70m" 8 "71~80m" 9 "81~90m" 10 "91~100m" 11 "101~200m" 12 "201~300m" 13 "301~400m" 14 "401m~" 15 "Error indicator";
VAL_ 698 IFSref_VehDst5Val 0 "No Value" 1 "1~10m" 2 "11~20m" 3 "21~30m" 4 "31~40m" 5 "41~50m" 6 "51~60m" 7 "61~70m" 8 "71~80m" 9 "81~90m" 10 "91~100m" 11 "101~200m" 12 "201~300m" 13 "301~400m" 14 "401m~" 15 "Error indicator";
VAL_ 698 IFSref_VehDst6Val 0 "No Value" 1 "1~10m" 2 "11~20m" 3 "21~30m" 4 "31~40m" 5 "41~50m" 6 "51~60m" 7 "61~70m" 8 "71~80m" 9 "81~90m" 10 "91~100m" 11 "101~200m" 12 "201~300m" 13 "301~400m" 14 "401m~" 15 "Error indicator";
VAL_ 698 IFSref_VehDst7Val 0 "No Value" 1 "1~10m" 2 "11~20m" 3 "21~30m" 4 "31~40m" 5 "41~50m" 6 "51~60m" 7 "61~70m" 8 "71~80m" 9 "81~90m" 10 "91~100m" 11 "101~200m" 12 "201~300m" 13 "301~400m" 14 "401m~" 15 "Error indicator";
VAL_ 698 IFSref_VehDst8Val 0 "No Value" 1 "1~10m" 2 "11~20m" 3 "21~30m" 4 "31~40m" 5 "41~50m" 6 "51~60m" 7 "61~70m" 8 "71~80m" 9 "81~90m" 10 "91~100m" 11 "101~200m" 12 "201~300m" 13 "301~400m" 14 "401m~" 15 "Error indicator";
VAL_ 698 IFSref_VehDst9Val 0 "No Value" 1 "1~10m" 2 "11~20m" 3 "21~30m" 4 "31~40m" 5 "41~50m" 6 "51~60m" 7 "61~70m" 8 "71~80m" 9 "81~90m" 10 "91~100m" 11 "101~200m" 12 "201~300m" 13 "301~400m" 14 "401m~" 15 "Error indicator";
VAL_ 698 IFSref_VehDst10Val 0 "No Value" 1 "1~10m" 2 "11~20m" 3 "21~30m" 4 "31~40m" 5 "41~50m" 6 "51~60m" 7 "61~70m" 8 "71~80m" 9 "81~90m" 10 "91~100m" 11 "101~200m" 12 "201~300m" 13 "301~400m" 14 "401m~" 15 "Error indicator";
VAL_ 736 MSLA_STATUS 0 "disabled" 1 "active" 2 "paused";
VAL_ 866 LEFT_LANE_LINE 0 "Not Detected" 1 "Low Confidence" 2 "Medium Confidence" 3 "High Confidence";
VAL_ 866 RIGHT_LANE_LINE 0 "Not Detected" 1 "Low Confidence" 2 "Medium Confidence" 3 "High Confidence";
VAL_ 1041 DRIVER_DOOR 0 "Closed" 1 "Opened";
VAL_ 1041 PASSENGER_DOOR 0 "Closed" 1 "Opened";
VAL_ 1041 PASSENGER_SEATBELT 0 "Unlatched" 1 "Latched";
VAL_ 1041 DRIVER_SEATBELT 0 "Unlatched" 1 "Latched";
VAL_ 1041 DRIVER_REAR_DOOR 0 "Closed" 1 "Opened";
VAL_ 1041 PASSENGER_REAR_DOOR 0 "Closed" 1 "Opened";
VAL_ 1144 DRIVE_MODE2 3 "Set Sport" 1 "Set Normal" 2 "Set Eco";
VAL_ 1240 DISTANCE_UNIT 1 "Miles" 0 "Kilometers";

BO_ 416 SCC_CONTROL: 32 ADRV
 SG_ CHECKSUM : 0|16@1+ (1,0) [0|65535] "" XXX
 SG_ COUNTER : 16|8@1+ (1,0) [0|255] "" XXX
 SG_ ACC_ObjDist : 24|11@1+ (0.1,0) [0|204.7] "m" XXX
 SG_ ACC_ObjRelSpd : 35|9@1+ (0.1,-16.4) [-16.4|34.7] "m/s" XXX
 SG_ SET_ME_3 : 45|2@0+ (1,0) [0|3] "" XXX
 SG_ ObjValid : 46|1@0+ (1,0) [0|3] "" XXX
 SG_ SET_ME_TMP_64 : 55|8@0+ (1,0) [0|63] "" XXX
 SG_ ZEROS_7 : 63|8@0+ (1,0) [0|255] "" XXX
 SG_ NEW_SIGNAL_1 : 64|2@1+ (1,0) [0|3] "" XXX
 SG_ MainMode_ACC : 66|1@1+ (1,0) [0|1] "" XXX
 SG_ ACCMode : 68|3@1+ (1,0) [0|7] "" XXX
 SG_ ZEROS_9 : 71|5@1+ (1,0) [0|15] "" XXX
 SG_ CRUISE_STANDSTILL : 76|1@1+ (1,0) [0|1] "" XXX
 SG_ ZEROS_5 : 77|11@1+ (1,0) [0|2047] "" XXX
 SG_ DISTANCE_SETTING : 88|3@1+ (1,0) [0|3] "" XXX
 SG_ ZEROS_8 : 95|5@0+ (1,0) [0|31] "" XXX
 SG_ VSetDis : 103|8@0+ (1,0) [0|255] "km/h or mph" XXX
 SG_ NEW_SIGNAL_6 : 104|1@0+ (1,0) [0|1] "" XXX
 SG_ SET_ME_2 : 105|3@1+ (1,0) [0|7] "" XXX
 SG_ NEW_SIGNAL_3 : 109|2@0+ (1,0) [0|1] "" XXX
 SG_ ZEROS_10 : 111|2@0+ (1,0) [0|3] "" XXX
 SG_ ZEROS_6 : 119|16@0+ (1,0) [0|65535] "" XXX
 SG_ aReqValue : 128|11@1+ (0.01,-10.23) [-10.23|10.24] "m/s^2" XXX
 SG_ aReqRaw : 140|11@1+ (0.01,-10.23) [-10.23|10.24] "m/s^2" XXX
 SG_ JerkUpperLimit : 158|7@0+ (0.1,0) [0|0] "" XXX
 SG_ JerkLowerLimit : 166|7@0+ (0.1,0) [0|12.7] "m/s^3" XXX
 SG_ NEW_SIGNAL_2 : 168|2@1+ (1,0) [0|3] "" XXX
 SG_ NEW_SIGNAL_8 : 170|4@1+ (1,0) [0|15] "" XXX
 SG_ OBJ_STATUS : 176|3@1+ (1,0) [0|7] "" XXX
 SG_ ZEROS_4 : 183|4@0+ (1,0) [0|63] "" XXX
 SG_ StopReq : 184|1@0+ (1,0) [0|1] "" XXX
 SG_ ZEROS_3 : 191|7@0+ (1,0) [0|127] "" XXX
 SG_ NEW_SIGNAL_15 : 192|11@1+ (0.1,0) [0|204.7] "m" XXX
 SG_ ZEROS_2 : 207|5@0+ (1,0) [0|63] "" XXX
 SG_ ZEROS : 215|48@0+ (1,0) [0|281474976710655] "" XXX
